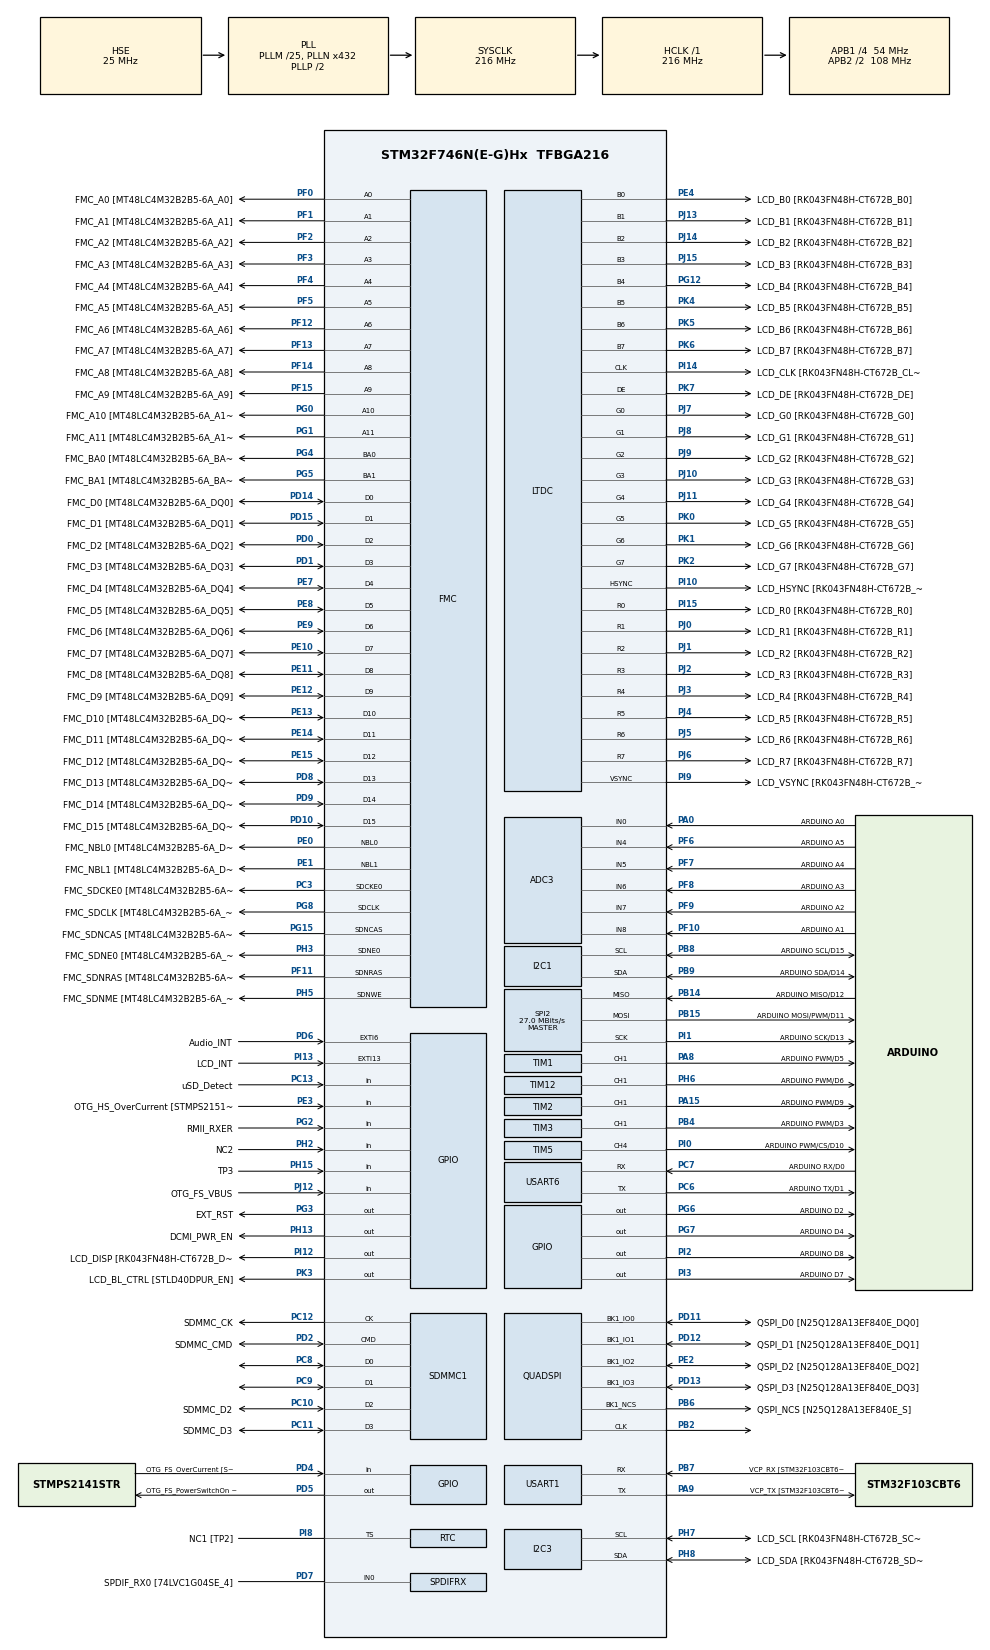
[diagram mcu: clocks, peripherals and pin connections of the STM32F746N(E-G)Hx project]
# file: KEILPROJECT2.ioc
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ADC3.Channel=ADC_CHANNEL_7
ADC3.Channel-0\#ChannelRegularConversion=ADC_CHANNEL_4
ADC3.Channel-IN0=ADC_CHANNEL_0
ADC3.Channel-IN4=ADC_CHANNEL_4
ADC3.Channel-IN5=ADC_CHANNEL_5
ADC3.Channel-IN6=ADC_CHANNEL_6
ADC3.Channel-IN7=ADC_CHANNEL_7
ADC3.Channel-IN8=ADC_CHANNEL_8
CORTEX_M7.CPU_DCache=Enabled
CORTEX_M7.CPU_ICache=Enabled
CORTEX_M7.FlashInterface=TCM_Enabled
I2C1.Timing=0x20404768
I2C3.Timing=0x20404768
LTDC.ActiveH=272
LTDC.ActiveW=480
Mcu.Family=STM32F7
Mcu.Name=STM32F746N(E-G)Hx
Mcu.Package=TFBGA216
NVIC.PriorityGroup=NVIC_PRIORITYGROUP_4
PA0/WKUP.GPIO_Label=ARDUINO A0
PA0/WKUP.GPIO_Mode=GPIO_MODE_ANALOG
PA0/WKUP.GPIO_PuPd=GPIO_NOPULL
PA0/WKUP.Signal=ADCx_IN0
PA1.GPIO_Label=RMII_REF_CLK [LAN8742A-CZ-TR_REFCLK0]
PA1.Signal=ETH_REF_CLK
PA10.GPIO_Label=OTG_FS_ID
PA10.Signal=USB_OTG_FS_ID
PA11.GPIO_Label=OTG_FS_N
PA11.Signal=USB_OTG_FS_DM
PA12.GPIO_Label=OTG_FS_P
PA12.Signal=USB_OTG_FS_DP
PA13.GPIO_Label=SWDIO
PA13.Mode=Serial_Wire
PA13.Signal=SYS_JTMS-SWDIO
PA14.GPIO_Label=SWCLK
PA14.Mode=Serial_Wire
PA14.Signal=SYS_JTCK-SWCLK
PA15.GPIO_Label=ARDUINO PWM/D9
PA15.GPIO_ModeDefaultPP=GPIO_MODE_AF_PP
PA15.GPIO_PuPd=GPIO_NOPULL
PA15.GPIO_Speed=GPIO_SPEED_FREQ_LOW
PA15.Signal=S_TIM2_CH1_ETR
PA2.GPIO_Label=RMII_MDIO [LAN8742A-CZ-TR_MDIO]
PA2.Signal=ETH_MDIO
PA3.GPIO_Label=ULPI_D0 [USB3320C-EZK_D0]
PA3.Signal=USB_OTG_HS_ULPI_D0
PA4.GPIO_Label=DCMI_HSYNC
PA4.Signal=DCMI_HSYNC
PA5.GPIO_Label=ULPI_CLK [USB3320C-EZK_CLKOUT]
PA5.Signal=USB_OTG_HS_ULPI_CK
PA6.Signal=DCMI_PIXCLK
PA7.GPIO_Label=RMII_CRS_DV [LAN8742A-CZ-TR_CRS_DV]
PA7.Signal=ETH_CRS_DV
PA8.GPIO_Label=ARDUINO PWM/D5
PA8.GPIO_ModeDefaultPP=GPIO_MODE_AF_PP
PA8.GPIO_PuPd=GPIO_NOPULL
PA8.GPIO_Speed=GPIO_SPEED_FREQ_LOW
PA8.Signal=S_TIM1_CH1
PA9.GPIO_Label=VCP_TX [STM32F103CBT6_PA3]
PA9.GPIO_Mode=GPIO_MODE_AF_PP
PA9.GPIO_PuPd=GPIO_NOPULL
PA9.GPIO_Speed=GPIO_SPEED_FREQ_LOW
PA9.Mode=Asynchronous
PA9.Signal=USART1_TX
PB0.GPIO_Label=ULPI_D1 [USB3320C-EZK_D1]
PB0.Signal=USB_OTG_HS_ULPI_D1
PB1.GPIO_Label=ULPI_D2 [USB3320C-EZK_D2]
PB1.Signal=USB_OTG_HS_ULPI_D2
PB10.GPIO_Label=ULPI_D3 [USB3320C-EZK_D3]
PB10.Signal=USB_OTG_HS_ULPI_D3
PB11.GPIO_Label=ULPI_D4 [USB3320C-EZK_D4]
PB11.Signal=USB_OTG_HS_ULPI_D4
PB12.GPIO_Label=ULPI_D5 [USB3320C-EZK_D5]
PB12.Signal=USB_OTG_HS_ULPI_D5
PB13.GPIO_Label=ULPI_D6 [USB3320C-EZK_D6]
PB13.Signal=USB_OTG_HS_ULPI_D6
PB14.GPIO_Label=ARDUINO MISO/D12
PB14.GPIO_Mode=GPIO_MODE_AF_PP
PB14.GPIO_PuPd=GPIO_NOPULL
PB14.GPIO_Speed=GPIO_SPEED_FREQ_LOW
PB14.Mode=Full_Duplex_Master
PB14.Signal=SPI2_MISO
PB15.GPIO_Label=ARDUINO MOSI/PWM/D11
PB15.GPIO_Mode=GPIO_MODE_AF_PP
PB15.GPIO_PuPd=GPIO_NOPULL
PB15.GPIO_Speed=GPIO_SPEED_FREQ_LOW
PB15.Mode=Full_Duplex_Master
PB15.Signal=SPI2_MOSI
PB2.Mode=Single Bank 1
PB2.Signal=QUADSPI_CLK
PB3.GPIO_Label=SWO
PB3.Signal=SYS_JTDO-SWO
PB4.GPIO_Label=ARDUINO PWM/D3
PB4.GPIO_ModeDefaultPP=GPIO_MODE_AF_PP
PB4.GPIO_PuPd=GPIO_NOPULL
PB4.GPIO_Speed=GPIO_SPEED_FREQ_LOW
PB4.Signal=S_TIM3_CH1
PB5.GPIO_Label=ULPI_D7 [USB3320C-EZK_D7]
PB5.Signal=USB_OTG_HS_ULPI_D7
PB6.GPIO_Label=QSPI_NCS [N25Q128A13EF840E_S]
PB6.Mode=Single Bank 1
PB6.Signal=QUADSPI_BK1_NCS
PB7.GPIO_Label=VCP_RX [STM32F103CBT6_PA2]
PB7.GPIO_Mode=GPIO_MODE_AF_PP
PB7.GPIO_PuPd=GPIO_NOPULL
PB7.GPIO_Speed=GPIO_SPEED_FREQ_LOW
PB7.Mode=Asynchronous
PB7.Signal=USART1_RX
PB8.GPIO_Label=ARDUINO SCL/D15
PB8.GPIO_Mode=GPIO_MODE_AF_OD
PB8.GPIO_PuPd=GPIO_NOPULL
PB8.GPIO_Speed=GPIO_SPEED_FREQ_LOW
PB8.Mode=I2C
PB8.Signal=I2C1_SCL
PB9.GPIO_Label=ARDUINO SDA/D14
PB9.GPIO_Mode=GPIO_MODE_AF_OD
PB9.GPIO_PuPd=GPIO_NOPULL
PB9.GPIO_Speed=GPIO_SPEED_FREQ_LOW
PB9.Mode=I2C
PB9.Signal=I2C1_SDA
PC0.GPIO_Label=ULPI_STP [USB3320C-EZK_STP]
PC0.Signal=USB_OTG_HS_ULPI_STP
PC1.GPIO_Label=RMII_MDC [LAN8742A-CZ-TR_MDC]
PC1.Signal=ETH_MDC
PC10.GPIO_Label=SDMMC_D2
PC10.Mode=SD_4_bits_Wide_bus
PC10.Signal=SDMMC1_D2
PC11.GPIO_Label=SDMMC_D3
PC11.Mode=SD_4_bits_Wide_bus
PC11.Signal=SDMMC1_D3
PC12.GPIO_Label=SDMMC_CK
PC12.Mode=SD_4_bits_Wide_bus
PC12.Signal=SDMMC1_CK
PC13.GPIO_Label=uSD_Detect
PC13.Signal=GPIO_Input
PC14/OSC32_IN.GPIO_Label=RCC_OSC32_IN
PC14/OSC32_IN.Mode=LSE-External-Oscillator
PC14/OSC32_IN.Signal=RCC_OSC32_IN
PC15/OSC32_OUT.GPIO_Label=RCC_OSC32_OUT
PC15/OSC32_OUT.Mode=LSE-External-Oscillator
PC15/OSC32_OUT.Signal=RCC_OSC32_OUT
PC2.GPIO_Label=ULPI_DIR [USB3320C-EZK_DIR]
PC2.Signal=USB_OTG_HS_ULPI_DIR
PC3.GPIO_Label=FMC_SDCKE0 [MT48LC4M32B2B5-6A_CKE]
PC3.Mode=SdramChipSelect1_1
PC3.Signal=FMC_SDCKE0
PC4.GPIO_Label=RMII_RXD0 [LAN8742A-CZ-TR_RXD0]
PC4.Signal=ETH_RXD0
PC5.GPIO_Label=RMII_RXD1 [LAN8742A-CZ-TR_RXD1]
PC5.Signal=ETH_RXD1
PC6.GPIO_Label=ARDUINO TX/D1
PC6.Mode=Asynchronous
PC6.Signal=USART6_TX
PC7.GPIO_Label=ARDUINO RX/D0
PC7.Mode=Asynchronous
PC7.Signal=USART6_RX
PC8.Mode=SD_4_bits_Wide_bus
PC8.Signal=SDMMC1_D0
PC9.Mode=SD_4_bits_Wide_bus
PC9.Signal=SDMMC1_D1
PD0.GPIO_Label=FMC_D2 [MT48LC4M32B2B5-6A_DQ2]
PD0.Signal=FMC_D2_DA2
PD1.GPIO_Label=FMC_D3 [MT48LC4M32B2B5-6A_DQ3]
PD1.Signal=FMC_D3_DA3
PD10.GPIO_Label=FMC_D15 [MT48LC4M32B2B5-6A_DQ15]
PD10.Signal=FMC_D15_DA15
PD11.GPIO_Label=QSPI_D0 [N25Q128A13EF840E_DQ0]
PD11.Mode=Single Bank 1
PD11.Signal=QUADSPI_BK1_IO0
PD12.GPIO_Label=QSPI_D1 [N25Q128A13EF840E_DQ1]
PD12.Mode=Single Bank 1
PD12.Signal=QUADSPI_BK1_IO1
PD13.GPIO_Label=QSPI_D3 [N25Q128A13EF840E_DQ3]
PD13.Mode=Single Bank 1
PD13.Signal=QUADSPI_BK1_IO3
PD14.GPIO_Label=FMC_D0 [MT48LC4M32B2B5-6A_DQ0]
PD14.Signal=FMC_D0_DA0
PD15.GPIO_Label=FMC_D1 [MT48LC4M32B2B5-6A_DQ1]
PD15.Signal=FMC_D1_DA1
PD2.GPIO_Label=SDMMC_CMD
PD2.Mode=SD_4_bits_Wide_bus
PD2.Signal=SDMMC1_CMD
PD3.GPIO_Label=DCMI_D5
PD3.Signal=DCMI_D5
PD4.GPIO_Label=OTG_FS_OverCurrent [STMPS2141STR_Fault]
PD4.Signal=GPIO_Input
PD5.GPIO_Label=OTG_FS_PowerSwitchOn [STMPS2141STR_EN]
PD5.PinState=GPIO_PIN_SET
PD5.Signal=GPIO_Output
PD6.GPIO_Label=Audio_INT
PD6.GPIO_ModeDefaultEXTI=GPIO_MODE_EVT_RISING
PD6.Signal=GPXTI6
PD7.GPIO_Label=SPDIF_RX0 [74LVC1G04SE_4]
PD7.Mode=IN0
PD7.Signal=SPDIFRX_IN0
PD8.GPIO_Label=FMC_D13 [MT48LC4M32B2B5-6A_DQ13]
PD8.Signal=FMC_D13_DA13
PD9.GPIO_Label=FMC_D14 [MT48LC4M32B2B5-6A_DQ14]
PD9.Signal=FMC_D14_DA14
PE0.GPIO_Label=FMC_NBL0 [MT48LC4M32B2B5-6A_DQM0]
PE0.Signal=FMC_NBL0
PE1.GPIO_Label=FMC_NBL1 [MT48LC4M32B2B5-6A_DQM1]
PE1.Signal=FMC_NBL1
PE10.GPIO_Label=FMC_D7 [MT48LC4M32B2B5-6A_DQ7]
PE10.Signal=FMC_D7_DA7
PE11.GPIO_Label=FMC_D8 [MT48LC4M32B2B5-6A_DQ8]
PE11.Signal=FMC_D8_DA8
PE12.GPIO_Label=FMC_D9 [MT48LC4M32B2B5-6A_DQ9]
PE12.Signal=FMC_D9_DA9
PE13.GPIO_Label=FMC_D10 [MT48LC4M32B2B5-6A_DQ10]
PE13.Signal=FMC_D10_DA10
PE14.GPIO_Label=FMC_D11 [MT48LC4M32B2B5-6A_DQ11]
PE14.Signal=FMC_D11_DA11
PE15.GPIO_Label=FMC_D12 [MT48LC4M32B2B5-6A_DQ12]
PE15.Signal=FMC_D12_DA12
PE2.GPIO_Label=QSPI_D2 [N25Q128A13EF840E_DQ2]
PE2.Mode=Single Bank 1
PE2.Signal=QUADSPI_BK1_IO2
PE3.GPIO_Label=OTG_HS_OverCurrent [STMPS2151STR_FAULT]
PE3.Signal=GPIO_Input
PE4.GPIO_Label=LCD_B0 [RK043FN48H-CT672B_B0]
PE4.Mode=RGB888
PE4.Signal=LTDC_B0
PE5.GPIO_Label=DCMI_D6
PE5.Signal=DCMI_D6
PE6.GPIO_Label=DCMI_D7
PE6.Signal=DCMI_D7
PE7.GPIO_Label=FMC_D4 [MT48LC4M32B2B5-6A_DQ4]
PE7.Signal=FMC_D4_DA4
PE8.GPIO_Label=FMC_D5 [MT48LC4M32B2B5-6A_DQ5]
PE8.Signal=FMC_D5_DA5
PE9.GPIO_Label=FMC_D6 [MT48LC4M32B2B5-6A_DQ6]
PE9.Signal=FMC_D6_DA6
PF0.GPIO_Label=FMC_A0 [MT48LC4M32B2B5-6A_A0]
PF0.Signal=FMC_A0
PF1.GPIO_Label=FMC_A1 [MT48LC4M32B2B5-6A_A1]
PF1.Signal=FMC_A1
PF10.GPIO_Label=ARDUINO A1
PF10.GPIO_Mode=GPIO_MODE_ANALOG
PF10.GPIO_PuPd=GPIO_NOPULL
PF10.Mode=IN8
PF10.Signal=ADC3_IN8
PF11.GPIO_Label=FMC_SDNRAS [MT48LC4M32B2B5-6A_RAS]
PF11.Signal=FMC_SDNRAS
PF12.GPIO_Label=FMC_A6 [MT48LC4M32B2B5-6A_A6]
PF12.Signal=FMC_A6
PF13.GPIO_Label=FMC_A7 [MT48LC4M32B2B5-6A_A7]
PF13.Signal=FMC_A7
PF14.GPIO_Label=FMC_A8 [MT48LC4M32B2B5-6A_A8]
PF14.Signal=FMC_A8
PF15.GPIO_Label=FMC_A9 [MT48LC4M32B2B5-6A_A9]
PF15.Signal=FMC_A9
PF2.GPIO_Label=FMC_A2 [MT48LC4M32B2B5-6A_A2]
PF2.Signal=FMC_A2
PF3.GPIO_Label=FMC_A3 [MT48LC4M32B2B5-6A_A3]
PF3.Signal=FMC_A3
PF4.GPIO_Label=FMC_A4 [MT48LC4M32B2B5-6A_A4]
PF4.Signal=FMC_A4
PF5.GPIO_Label=FMC_A5 [MT48LC4M32B2B5-6A_A5]
PF5.Signal=FMC_A5
PF6.GPIO_Label=ARDUINO A5
PF6.GPIO_Mode=GPIO_MODE_ANALOG
PF6.GPIO_PuPd=GPIO_NOPULL
PF6.Mode=IN4
PF6.Signal=ADC3_IN4
PF7.GPIO_Label=ARDUINO A4
PF7.GPIO_Mode=GPIO_MODE_ANALOG
PF7.GPIO_PuPd=GPIO_NOPULL
PF7.Mode=IN5
PF7.Signal=ADC3_IN5
PF8.GPIO_Label=ARDUINO A3
PF8.GPIO_Mode=GPIO_MODE_ANALOG
PF8.GPIO_PuPd=GPIO_NOPULL
PF8.Mode=IN6
PF8.Signal=ADC3_IN6
PF9.GPIO_Label=ARDUINO A2
PF9.GPIO_Mode=GPIO_MODE_ANALOG
PF9.GPIO_PuPd=GPIO_NOPULL
PF9.Mode=IN7
PF9.Signal=ADC3_IN7
PG0.GPIO_Label=FMC_A10 [MT48LC4M32B2B5-6A_A10]
PG0.Signal=FMC_A10
PG1.GPIO_Label=FMC_A11 [MT48LC4M32B2B5-6A_A11]
PG1.Signal=FMC_A11
PG10.GPIO_Label=SAI2_SDB [WM8994ECS/R_ADCDAT1]
PG10.Signal=SAI2_SD_B
PG11.GPIO_Label=RMII_TX_EN [LAN8742A-CZ-TR_TXEN]
PG11.Signal=ETH_TX_EN
PG12.GPIO_Label=LCD_B4 [RK043FN48H-CT672B_B4]
PG12.Mode=RGB888
PG12.Signal=LTDC_B4
PG13.GPIO_Label=RMII_TXD0 [LAN8742A-CZ-TR_TXD0]
PG13.Signal=ETH_TXD0
PG14.GPIO_Label=RMII_TXD1 [LAN8742A-CZ-TR_TXD1]
PG14.Signal=ETH_TXD1
PG15.GPIO_Label=FMC_SDNCAS [MT48LC4M32B2B5-6A_CAS]
PG15.Signal=FMC_SDNCAS
PG2.GPIO_Label=RMII_RXER
PG2.Signal=GPIO_Input
PG3.GPIO_Label=EXT_RST
PG3.Signal=GPIO_Output
PG4.GPIO_Label=FMC_BA0 [MT48LC4M32B2B5-6A_BA0]
PG4.Signal=FMC_A14_BA0
PG5.GPIO_Label=FMC_BA1 [MT48LC4M32B2B5-6A_BA1]
PG5.Signal=FMC_A15_BA1
PG6.GPIO_Label=ARDUINO D2
PG6.Signal=GPIO_Output
PG7.GPIO_Label=ARDUINO D4
PG7.Signal=GPIO_Output
PG8.GPIO_Label=FMC_SDCLK [MT48LC4M32B2B5-6A_CLK]
PG8.Signal=FMC_SDCLK
PG9.GPIO_Label=DCMI_VSYNC
PG9.Signal=DCMI_VSYNC
PH0/OSC_IN.GPIO_Label=OSC_25M [NZ2520SB-25.00M_OUT]
PH0/OSC_IN.Mode=HSE-External-Oscillator
PH0/OSC_IN.Signal=RCC_OSC_IN
PH1/OSC_OUT.Mode=HSE-External-Oscillator
PH1/OSC_OUT.Signal=RCC_OSC_OUT
PH10.GPIO_Label=DCMI_D1
PH10.Signal=DCMI_D1
PH11.GPIO_Label=DCMI_D2
PH11.Signal=DCMI_D2
PH12.GPIO_Label=DCMI_D3
PH12.Signal=DCMI_D3
PH13.GPIO_Label=DCMI_PWR_EN
PH13.Signal=GPIO_Output
PH14.GPIO_Label=DCMI_D4
PH14.Signal=DCMI_D4
PH15.GPIO_Label=TP3
PH15.Signal=GPIO_Input
PH2.GPIO_Label=NC2
PH2.Signal=GPIO_Input
PH3.GPIO_Label=FMC_SDNE0 [MT48LC4M32B2B5-6A_CS]
PH3.Mode=SdramChipSelect1_1
PH3.Signal=FMC_SDNE0
PH4.GPIO_Label=ULPI_NXT [USB3320C-EZK_NXT]
PH4.Signal=USB_OTG_HS_ULPI_NXT
PH5.GPIO_Label=FMC_SDNME [MT48LC4M32B2B5-6A_WE]
PH5.Signal=FMC_SDNWE
PH6.GPIO_Label=ARDUINO PWM/D6
PH6.Signal=S_TIM12_CH1
PH7.GPIO_Label=LCD_SCL [RK043FN48H-CT672B_SCL]
PH7.Mode=I2C
PH7.Signal=I2C3_SCL
PH8.GPIO_Label=LCD_SDA [RK043FN48H-CT672B_SDA]
PH8.Mode=I2C
PH8.Signal=I2C3_SDA
PH9.GPIO_Label=DCMI_D0
PH9.Signal=DCMI_D0
PI0.GPIO_Label=ARDUINO PWM/CS/D10
PI0.GPIO_ModeDefaultPP=GPIO_MODE_AF_PP
PI0.GPIO_PuPd=GPIO_NOPULL
PI0.GPIO_Speed=GPIO_SPEED_FREQ_LOW
PI0.Signal=S_TIM5_CH4
PI1.GPIO_Label=ARDUINO SCK/D13
PI1.GPIO_Mode=GPIO_MODE_AF_PP
PI1.GPIO_PuPd=GPIO_NOPULL
PI1.GPIO_Speed=GPIO_SPEED_FREQ_LOW
PI1.Mode=Full_Duplex_Master
PI1.Signal=SPI2_SCK
PI10.GPIO_Label=LCD_HSYNC [RK043FN48H-CT672B_HSYNC]
PI10.Mode=RGB888
PI10.Signal=LTDC_HSYNC
PI12.GPIO_Label=LCD_DISP [RK043FN48H-CT672B_DISP] 
PI12.Signal=GPIO_Output
PI13.GPIO_Label=LCD_INT
PI13.GPIO_ModeDefaultEXTI=GPIO_MODE_EVT_RISING
PI13.Signal=GPXTI13
PI14.GPIO_Label=LCD_CLK [RK043FN48H-CT672B_CLK]
PI14.Mode=RGB888
PI14.Signal=LTDC_CLK
PI15.GPIO_Label=LCD_R0 [RK043FN48H-CT672B_R0]
PI15.Mode=RGB888
PI15.Signal=LTDC_R0
PI2.GPIO_Label=ARDUINO D8
PI2.Signal=GPIO_Output
PI3.GPIO_Label=ARDUINO D7
PI3.Signal=GPIO_Output
PI4.GPIO_Label=SAI2_MCLKA [WM8994ECS/R_MCLK1]
PI4.Signal=SAI2_MCLK_A
PI5.GPIO_Label=SAI2_SCKA [WM8994ECS/R_BCLK1]
PI5.Signal=SAI2_SCK_A
PI6.GPIO_Label=SAI2_SDA [WM8994ECS/R_DACDAT1]
PI6.Signal=SAI2_SD_A
PI7.GPIO_Label=SAI2_FSA [WM8994ECS/R_LRCLK1]
PI7.Signal=SAI2_FS_A
PI8.GPIO_Label=NC1 [TP2]
PI8.Mode=Timestamp enabled - Input Enabled to TS
PI8.Signal=RTC_TS
PI9.GPIO_Label=LCD_VSYNC [RK043FN48H-CT672B_VSYNC]
PI9.Mode=RGB888
PI9.Signal=LTDC_VSYNC
PJ0.GPIO_Label=LCD_R1 [RK043FN48H-CT672B_R1]
PJ0.Mode=RGB888
PJ0.Signal=LTDC_R1
PJ1.GPIO_Label=LCD_R2 [RK043FN48H-CT672B_R2]
PJ1.Mode=RGB888
PJ1.Signal=LTDC_R2
PJ10.GPIO_Label=LCD_G3 [RK043FN48H-CT672B_G3]
PJ10.Mode=RGB888
PJ10.Signal=LTDC_G3
PJ11.GPIO_Label=LCD_G4 [RK043FN48H-CT672B_G4]
PJ11.Mode=RGB888
PJ11.Signal=LTDC_G4
PJ12.GPIO_Label=OTG_FS_VBUS
PJ12.Signal=GPIO_Input
PJ13.GPIO_Label=LCD_B1 [RK043FN48H-CT672B_B1]
PJ13.Mode=RGB888
PJ13.Signal=LTDC_B1
PJ14.GPIO_Label=LCD_B2 [RK043FN48H-CT672B_B2]
PJ14.Mode=RGB888
PJ14.Signal=LTDC_B2
PJ15.GPIO_Label=LCD_B3 [RK043FN48H-CT672B_B3]
PJ15.Mode=RGB888
PJ15.Signal=LTDC_B3
PJ2.GPIO_Label=LCD_R3 [RK043FN48H-CT672B_R3]
PJ2.Mode=RGB888
PJ2.Signal=LTDC_R3
PJ3.GPIO_Label=LCD_R4 [RK043FN48H-CT672B_R4]
PJ3.Mode=RGB888
PJ3.Signal=LTDC_R4
PJ4.GPIO_Label=LCD_R5 [RK043FN48H-CT672B_R5]
PJ4.Mode=RGB888
PJ4.Signal=LTDC_R5
PJ5.GPIO_Label=LCD_R6 [RK043FN48H-CT672B_R6]
PJ5.Mode=RGB888
PJ5.Signal=LTDC_R6
PJ6.GPIO_Label=LCD_R7 [RK043FN48H-CT672B_R7]
PJ6.Mode=RGB888
PJ6.Signal=LTDC_R7
PJ7.GPIO_Label=LCD_G0 [RK043FN48H-CT672B_G0]
PJ7.Mode=RGB888
PJ7.Signal=LTDC_G0
PJ8.GPIO_Label=LCD_G1 [RK043FN48H-CT672B_G1]
PJ8.Mode=RGB888
PJ8.Signal=LTDC_G1
PJ9.GPIO_Label=LCD_G2 [RK043FN48H-CT672B_G2]
PJ9.Mode=RGB888
PJ9.Signal=LTDC_G2
PK0.GPIO_Label=LCD_G5 [RK043FN48H-CT672B_G5]
PK0.Mode=RGB888
PK0.Signal=LTDC_G5
PK1.GPIO_Label=LCD_G6 [RK043FN48H-CT672B_G6]
PK1.Mode=RGB888
PK1.Signal=LTDC_G6
PK2.GPIO_Label=LCD_G7 [RK043FN48H-CT672B_G7]
PK2.Mode=RGB888
PK2.Signal=LTDC_G7
PK3.GPIO_Label=LCD_BL_CTRL [STLD40DPUR_EN]
PK3.Signal=GPIO_Output
PK4.GPIO_Label=LCD_B5 [RK043FN48H-CT672B_B5]
PK4.Mode=RGB888
PK4.Signal=LTDC_B5
PK5.GPIO_Label=LCD_B6 [RK043FN48H-CT672B_B6]
PK5.Mode=RGB888
PK5.Signal=LTDC_B6
PK6.GPIO_Label=LCD_B7 [RK043FN48H-CT672B_B7]
PK6.Mode=RGB888
PK6.Signal=LTDC_B7
PK7.GPIO_Label=LCD_DE [RK043FN48H-CT672B_DE]
PK7.Mode=RGB888
PK7.Signal=LTDC_DE
ProjectManager.HeapSize=0x200
ProjectManager.StackSize=0x3000
ProjectManager.TargetToolchain=MDK-ARM V5
RCC.AHBFreq_Value=216000000
RCC.APB1CLKDivider=RCC_HCLK_DIV4
RCC.APB1Freq_Value=54000000
RCC.APB1TimFreq_Value=108000000
RCC.APB2CLKDivider=RCC_HCLK_DIV2
RCC.APB2Freq_Value=108000000
RCC.APB2TimFreq_Value=216000000
RCC.CortexFreq_Value=216000000
RCC.HCLKFreq_Value=216000000
RCC.HSE_VALUE=25000000
RCC.HSI_VALUE=16000000
RCC.PLLI2SN=100
RCC.PLLM=25
RCC.PLLN=432
RCC.PLLQ=9
RCC.PLLSAIN=100
RCC.PLLSourceVirtual=RCC_PLLSOURCE_HSE
RCC.SDMMCClockSelection=RCC_SDMMC1CLKSOURCE_CLK48
RCC.SYSCLKFreq_VALUE=216000000
RCC.SYSCLKSource=RCC_SYSCLKSOURCE_PLLCLK
RCC.USBFreq_Value=48000000
RCC.VCOOutputFreq_Value=432000000
RTC.Alarm-Alarm\ A=RTC_ALARM_A
RTC.Alarm_B-Alarm\ B=RTC_ALARM_B
SDMMC1.ClockDiv=2
SH.ADCx_IN0.0=ADC3_IN0,IN0
SH.FMC_A0.0=FMC_A0,12b-sda1
SH.FMC_A1.0=FMC_A1,12b-sda1
SH.FMC_A10.0=FMC_A10,12b-sda1
SH.FMC_A11.0=FMC_A11,12b-sda1
SH.FMC_A14_BA0.0=FMC_BA0,FourSdramBanks1
SH.FMC_A15_BA1.0=FMC_BA1,FourSdramBanks1
SH.FMC_A2.0=FMC_A2,12b-sda1
SH.FMC_A3.0=FMC_A3,12b-sda1
SH.FMC_A4.0=FMC_A4,12b-sda1
SH.FMC_A5.0=FMC_A5,12b-sda1
SH.FMC_A6.0=FMC_A6,12b-sda1
SH.FMC_A7.0=FMC_A7,12b-sda1
SH.FMC_A8.0=FMC_A8,12b-sda1
SH.FMC_A9.0=FMC_A9,12b-sda1
SH.FMC_D0_DA0.0=FMC_D0,sd-16b-d1
SH.FMC_D10_DA10.0=FMC_D10,sd-16b-d1
SH.FMC_D11_DA11.0=FMC_D11,sd-16b-d1
SH.FMC_D12_DA12.0=FMC_D12,sd-16b-d1
SH.FMC_D13_DA13.0=FMC_D13,sd-16b-d1
SH.FMC_D14_DA14.0=FMC_D14,sd-16b-d1
SH.FMC_D15_DA15.0=FMC_D15,sd-16b-d1
SH.FMC_D1_DA1.0=FMC_D1,sd-16b-d1
SH.FMC_D2_DA2.0=FMC_D2,sd-16b-d1
SH.FMC_D3_DA3.0=FMC_D3,sd-16b-d1
SH.FMC_D4_DA4.0=FMC_D4,sd-16b-d1
SH.FMC_D5_DA5.0=FMC_D5,sd-16b-d1
SH.FMC_D6_DA6.0=FMC_D6,sd-16b-d1
SH.FMC_D7_DA7.0=FMC_D7,sd-16b-d1
SH.FMC_D8_DA8.0=FMC_D8,sd-16b-d1
SH.FMC_D9_DA9.0=FMC_D9,sd-16b-d1
SH.FMC_NBL0.0=FMC_NBL0,Sd2ByteEnable1
SH.FMC_NBL1.0=FMC_NBL1,Sd2ByteEnable1
SH.FMC_SDCLK.0=FMC_SDCLK,12b-sda1
SH.FMC_SDNCAS.0=FMC_SDNCAS,12b-sda1
SH.FMC_SDNRAS.0=FMC_SDNRAS,12b-sda1
SH.FMC_SDNWE.0=FMC_SDNWE,12b-sda1
SH.S_TIM12_CH1.0=TIM12_CH1,PWM Generation1 CH1
SH.S_TIM1_CH1.0=TIM1_CH1,PWM Generation1 CH1
SH.S_TIM2_CH1_ETR.0=TIM2_CH1,PWM Generation1 CH1
SH.S_TIM3_CH1.0=TIM3_CH1,PWM Generation1 CH1
SH.S_TIM5_CH4.0=TIM5_CH4,PWM Generation4 CH4
SPI2.CalculateBaudRate=27.0 MBits/s
SPI2.Direction=SPI_DIRECTION_2LINES
SPI2.Mode=SPI_MODE_MASTER
SPI2.VirtualType=VM_MASTER
TIM1.Channel-PWM\ Generation1\ CH1=TIM_CHANNEL_1
TIM12.Channel-PWM\ Generation1\ CH1=TIM_CHANNEL_1
TIM2.Channel-PWM\ Generation1\ CH1=TIM_CHANNEL_1
TIM3.Channel-PWM\ Generation1\ CH1=TIM_CHANNEL_1
TIM5.Channel-PWM\ Generation4\ CH4=TIM_CHANNEL_4
USART1.VirtualMode-Asynchronous=VM_ASYNC
USART6.VirtualMode-Asynchronous=VM_ASYNC
VP_FATFS_VS_SDIO.Mode=SDIO
VP_RTC_VS_RTC_Activate.Mode=RTC_Enabled
VP_RTC_VS_RTC_Alarm_A_Intern.Mode=Alarm A
VP_RTC_VS_RTC_Alarm_B_Intern.Mode=Alarm B
VP_RTC_VS_RTC_Calendar.Mode=RTC_Calendar
VP_TIM1_VS_ClockSourceINT.Mode=Internal
VP_TIM2_VS_ClockSourceINT.Mode=Internal
VP_TIM3_VS_ClockSourceINT.Mode=Internal
VP_TIM5_VS_ClockSourceINT.Mode=Internal
VP_TIM8_VS_ClockSourceINT.Mode=Internal
board=STM32F746G-DISCO

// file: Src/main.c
/**
  ******************************************************************************
  * File Name          : main.c
  * Description        : Main program body
  ******************************************************************************
  * This notice applies to any and all portions of this file
  * that are not between comment pairs USER CODE BEGIN and
  * USER CODE END. Other portions of this file, whether
  * inserted by the user or by software development tools
  * are owned by their respective copyright owners.
  *
  * Copyright (c) 2017 STMicroelectronics International N.V.
  * All rights reserved.
  *
  * Redistribution and use in source and binary forms, with or without
  * modification, are permitted, provided that the following conditions are met:
  *
  * 1. Redistribution of source code must retain the above copyright notice,
  *    this list of conditions and the following disclaimer.
  * 2. Redistributions in binary form must reproduce the above copyright notice,
  *    this list of conditions and the following disclaimer in the documentation
  *    and/or other materials provided with the distribution.
  * 3. Neither the name of STMicroelectronics nor the names of other
  *    contributors to this software may be used to endorse or promote products
  *    derived from this software without specific written permission.
  * 4. This software, including modifications and/or derivative works of this
  *    software, must execute solely and exclusively on microcontroller or
  *    microprocessor devices manufactured by or for STMicroelectronics.
  * 5. Redistribution and use of this software other than as permitted under
  *    this license is void and will automatically terminate your rights under
  *    this license.
  *
  * THIS SOFTWARE IS PROVIDED BY STMICROELECTRONICS AND CONTRIBUTORS "AS IS"
  * AND ANY EXPRESS, IMPLIED OR STATUTORY WARRANTIES, INCLUDING, BUT NOT
  * LIMITED TO, THE IMPLIED WARRANTIES OF MERCHANTABILITY, FITNESS FOR A
  * PARTICULAR PURPOSE AND NON-INFRINGEMENT OF THIRD PARTY INTELLECTUAL PROPERTY
  * RIGHTS ARE DISCLAIMED TO THE FULLEST EXTENT PERMITTED BY LAW. IN NO EVENT
  * SHALL STMICROELECTRONICS OR CONTRIBUTORS BE LIABLE FOR ANY DIRECT, INDIRECT,
  * INCIDENTAL, SPECIAL, EXEMPLARY, OR CONSEQUENTIAL DAMAGES (INCLUDING, BUT NOT
  * LIMITED TO, PROCUREMENT OF SUBSTITUTE GOODS OR SERVICES; LOSS OF USE, DATA,
  * OR PROFITS; OR BUSINESS INTERRUPTION) HOWEVER CAUSED AND ON ANY THEORY OF
  * LIABILITY, WHETHER IN CONTRACT, STRICT LIABILITY, OR TORT (INCLUDING
  * NEGLIGENCE OR OTHERWISE) ARISING IN ANY WAY OUT OF THE USE OF THIS SOFTWARE,
  * EVEN IF ADVISED OF THE POSSIBILITY OF SUCH DAMAGE.
  *
  ******************************************************************************
  */
#include "main.h"
#include "stm32f7xx_hal.h"
#include "fatfs.h"

/* USER CODE BEGIN Includes */

//YTB tutorial method S @ //<<<<SD CARD file writing demo>>>S>>
FRESULT res;
FATFS SDFatFS;
FIL myFile;
char bufferwr[30] = "Manojkumar\r\n" ;
char bufferrd[30];
char SDPath[10];
uint32_t byteswritten, bytesread;
extern void runonce();
extern void guiEventLoop(void);
enum _bool
{
false = 0,
true =1
};typedef enum _bool boolean;

//YTB tutorial method E

/*<<---------TEST_CODES----S----->>*/
/*UGFX NOTEPAD CODE BEGIN*/
//#define COLOFR_SIZE	20
//#define PEN_SIZE	20
//#define OFFSET		3

//#define COLOR_BOX(a)		(ev.x >= a && ev.x <= a + COLOR_SIZE)
//#define PEN_BOX(a)			(ev.y >= a && ev.y <= a + COLOR_SIZE)
//#define GET_COLOR(a)		(COLOR_BOX(a * COLOR_SIZE + OFFSET))
//#define GET_PEN(a)			(PEN_BOX(a * 2 * PEN_SIZE + OFFSET))
//#define DRAW_COLOR(a)		(a * COLOR_SIZE + OFFSET)
//#define DRAW_PEN(a)			(a * 2 * PEN_SIZE + OFFSET)
//#define DRAW_AREA(x, y)		(x >= PEN_SIZE + OFFSET + 3 && x <= gdispGetWidth() && \
//							 y >= COLOR_SIZE + OFFSET + 3 && y <= gdispGetHeight())
//#include "gfx.h"
//#include "gui.h"
//#include "ugfx_ex.h"
/*UGFX NOTEPAD CODE END*/

//NOTEPAD GUI RELATED BEGIN/
//		extern void gfxInit(void);
//		extern void drawScreen(void);
//extern void rundisplay(void);
//NOTEPAD GUI RELATED END*/
/*<<---------TEST_CODES----E----->>*/
extern int ugfxfatfsdemo();
/* USER CODE END Includes */

ADC_HandleTypeDef hadc3;

I2C_HandleTypeDef hi2c1;
I2C_HandleTypeDef hi2c3;

LTDC_HandleTypeDef hltdc;

QSPI_HandleTypeDef hqspi;

RTC_HandleTypeDef hrtc;

SD_HandleTypeDef hsd1;

SPDIFRX_HandleTypeDef hspdif;

SPI_HandleTypeDef hspi2;

TIM_HandleTypeDef htim1;
TIM_HandleTypeDef htim2;
TIM_HandleTypeDef htim3;
TIM_HandleTypeDef htim5;
TIM_HandleTypeDef htim8;
TIM_HandleTypeDef htim12;

UART_HandleTypeDef huart1;
UART_HandleTypeDef huart6;

SDRAM_HandleTypeDef hsdram1;

/* USER CODE BEGIN PV */
/* Private variables ---------------------------------------------------------*/

/* USER CODE END PV */

void SystemClock_Config(void);
static void MX_GPIO_Init(void);
static void MX_ADC3_Init(void);
static void MX_FMC_Init(void);
static void MX_I2C1_Init(void);
static void MX_I2C3_Init(void);
static void MX_LTDC_Init(void);
static void MX_QUADSPI_Init(void);
static void MX_RTC_Init(void);
static void MX_SDMMC1_SD_Init(void);
static void MX_SPDIFRX_Init(void);
static void MX_SPI2_Init(void);
static void MX_TIM1_Init(void);
static void MX_TIM2_Init(void);
static void MX_TIM3_Init(void);
static void MX_TIM5_Init(void);
static void MX_TIM8_Init(void);
static void MX_TIM12_Init(void);
static void MX_USART1_UART_Init(void);
static void MX_USART6_UART_Init(void);

void HAL_TIM_MspPostInit(TIM_HandleTypeDef *htim);

/* USER CODE BEGIN PFP */
/* Private function prototypes -----------------------------------------------*/

/* USER CODE END PFP */

/* USER CODE BEGIN 0 */
//int RoughAdjValue = 10;
//GEventMouse		ev;
/* USER CODE END 0 */

int main(void)
{

  /* Enable I-Cache-------------------------------------------------------------*/
  SCB_EnableICache();

  /* Enable D-Cache-------------------------------------------------------------*/
  SCB_EnableDCache();

  /* MCU Configuration----------------------------------------------------------*/

  /* Reset of all peripherals, Initializes the Flash interface and the Systick. */
  HAL_Init();

  /* Configure the system clock */
  SystemClock_Config();

  /* Initialize all configured peripherals */
  MX_GPIO_Init();
  MX_ADC3_Init();
  MX_FMC_Init();
  MX_I2C1_Init();
  MX_I2C3_Init();
  MX_LTDC_Init();
  MX_QUADSPI_Init();
  MX_RTC_Init();
  MX_SDMMC1_SD_Init();
  MX_SPDIFRX_Init();
  MX_SPI2_Init();
  MX_TIM1_Init();
  MX_TIM2_Init();
  MX_TIM3_Init();
  MX_TIM5_Init();
  MX_TIM8_Init();
  MX_TIM12_Init();
  MX_USART1_UART_Init();
  MX_USART6_UART_Init();
  MX_FATFS_Init();

  /* USER CODE BEGIN 2 */
	 //<<<<SD CARD file writing demo>>>S>>
	 res = BSP_SD_Init();
	 res = f_mount(&SDFatFS, "", 1);
	 res = f_open(&myFile, "manoj.txt", FA_OPEN_ALWAYS|FA_WRITE|FA_WRITE);
	 res = f_lseek(&myFile, f_size(&myFile));
	 //f_printf(&myFile, "%s", bufferwr);
	 f_close(&myFile);
	 //<<<<SD CARD file writing demo>>>E>>
		//runonce();
		//guiEventLoop();
	 rundisplay();
	 //ugfxfatfsdemo();
  /* USER CODE END 2 */

  /* Infinite loop */
  while (1)
  {

  }

}

/** System Clock Configuration
*/
void SystemClock_Config(void)
{

  RCC_OscInitTypeDef RCC_OscInitStruct;
  RCC_ClkInitTypeDef RCC_ClkInitStruct;
  RCC_PeriphCLKInitTypeDef PeriphClkInitStruct;

    /**Configure the main internal regulator output voltage
    */
  __HAL_RCC_PWR_CLK_ENABLE();

  __HAL_PWR_VOLTAGESCALING_CONFIG(PWR_REGULATOR_VOLTAGE_SCALE1);

    /**Initializes the CPU, AHB and APB busses clocks
    */
  RCC_OscInitStruct.OscillatorType = RCC_OSCILLATORTYPE_LSI|RCC_OSCILLATORTYPE_HSE;
  RCC_OscInitStruct.HSEState = RCC_HSE_ON;
  RCC_OscInitStruct.LSIState = RCC_LSI_ON;
  RCC_OscInitStruct.PLL.PLLState = RCC_PLL_ON;
  RCC_OscInitStruct.PLL.PLLSource = RCC_PLLSOURCE_HSE;
  RCC_OscInitStruct.PLL.PLLM = 25;
  RCC_OscInitStruct.PLL.PLLN = 432;
  RCC_OscInitStruct.PLL.PLLP = RCC_PLLP_DIV2;
  RCC_OscInitStruct.PLL.PLLQ = 9;
  if (HAL_RCC_OscConfig(&RCC_OscInitStruct) != HAL_OK)
  {
    _Error_Handler(__FILE__, __LINE__);
  }

    /**Activate the Over-Drive mode
    */
  if (HAL_PWREx_EnableOverDrive() != HAL_OK)
  {
    _Error_Handler(__FILE__, __LINE__);
  }

    /**Initializes the CPU, AHB and APB busses clocks
    */
  RCC_ClkInitStruct.ClockType = RCC_CLOCKTYPE_HCLK|RCC_CLOCKTYPE_SYSCLK
                              |RCC_CLOCKTYPE_PCLK1|RCC_CLOCKTYPE_PCLK2;
  RCC_ClkInitStruct.SYSCLKSource = RCC_SYSCLKSOURCE_PLLCLK;
  RCC_ClkInitStruct.AHBCLKDivider = RCC_SYSCLK_DIV1;
  RCC_ClkInitStruct.APB1CLKDivider = RCC_HCLK_DIV4;
  RCC_ClkInitStruct.APB2CLKDivider = RCC_HCLK_DIV2;

  if (HAL_RCC_ClockConfig(&RCC_ClkInitStruct, FLASH_LATENCY_7) != HAL_OK)
  {
    _Error_Handler(__FILE__, __LINE__);
  }

  PeriphClkInitStruct.PeriphClockSelection = RCC_PERIPHCLK_SPDIFRX|RCC_PERIPHCLK_LTDC
                              |RCC_PERIPHCLK_RTC|RCC_PERIPHCLK_USART1
                              |RCC_PERIPHCLK_USART6|RCC_PERIPHCLK_I2C1
                              |RCC_PERIPHCLK_I2C3|RCC_PERIPHCLK_SDMMC1
                              |RCC_PERIPHCLK_CLK48;
  PeriphClkInitStruct.PLLI2S.PLLI2SN = 100;
  PeriphClkInitStruct.PLLI2S.PLLI2SP = RCC_PLLP_DIV2;
  PeriphClkInitStruct.PLLI2S.PLLI2SR = 2;
  PeriphClkInitStruct.PLLI2S.PLLI2SQ = 2;
  PeriphClkInitStruct.PLLSAI.PLLSAIN = 100;
  PeriphClkInitStruct.PLLSAI.PLLSAIR = 2;
  PeriphClkInitStruct.PLLSAI.PLLSAIQ = 2;
  PeriphClkInitStruct.PLLSAI.PLLSAIP = RCC_PLLSAIP_DIV2;
  PeriphClkInitStruct.PLLI2SDivQ = 1;
  PeriphClkInitStruct.PLLSAIDivQ = 1;
  PeriphClkInitStruct.PLLSAIDivR = RCC_PLLSAIDIVR_2;
  PeriphClkInitStruct.RTCClockSelection = RCC_RTCCLKSOURCE_LSI;
  PeriphClkInitStruct.Usart1ClockSelection = RCC_USART1CLKSOURCE_PCLK2;
  PeriphClkInitStruct.Usart6ClockSelection = RCC_USART6CLKSOURCE_PCLK2;
  PeriphClkInitStruct.I2c1ClockSelection = RCC_I2C1CLKSOURCE_PCLK1;
  PeriphClkInitStruct.I2c3ClockSelection = RCC_I2C3CLKSOURCE_PCLK1;
  PeriphClkInitStruct.Clk48ClockSelection = RCC_CLK48SOURCE_PLL;
  PeriphClkInitStruct.Sdmmc1ClockSelection = RCC_SDMMC1CLKSOURCE_CLK48;
  if (HAL_RCCEx_PeriphCLKConfig(&PeriphClkInitStruct) != HAL_OK)
  {
    _Error_Handler(__FILE__, __LINE__);
  }

    /**Configure the Systick interrupt time
    */
  HAL_SYSTICK_Config(HAL_RCC_GetHCLKFreq()/1000);

    /**Configure the Systick
    */
  HAL_SYSTICK_CLKSourceConfig(SYSTICK_CLKSOURCE_HCLK);

  /* SysTick_IRQn interrupt configuration */
  HAL_NVIC_SetPriority(SysTick_IRQn, 0, 0);
}

/* ADC3 init function */
static void MX_ADC3_Init(void)
{

  ADC_ChannelConfTypeDef sConfig;

    /**Configure the global features of the ADC (Clock, Resolution, Data Alignment and number of conversion)
    */
  hadc3.Instance = ADC3;
  hadc3.Init.ClockPrescaler = ADC_CLOCK_SYNC_PCLK_DIV4;
  hadc3.Init.Resolution = ADC_RESOLUTION_12B;
  hadc3.Init.ScanConvMode = DISABLE;
  hadc3.Init.ContinuousConvMode = DISABLE;
  hadc3.Init.DiscontinuousConvMode = DISABLE;
  hadc3.Init.ExternalTrigConvEdge = ADC_EXTERNALTRIGCONVEDGE_NONE;
  hadc3.Init.ExternalTrigConv = ADC_SOFTWARE_START;
  hadc3.Init.DataAlign = ADC_DATAALIGN_RIGHT;
  hadc3.Init.NbrOfConversion = 1;
  hadc3.Init.DMAContinuousRequests = DISABLE;
  hadc3.Init.EOCSelection = ADC_EOC_SINGLE_CONV;
  if (HAL_ADC_Init(&hadc3) != HAL_OK)
  {
    _Error_Handler(__FILE__, __LINE__);
  }

    /**Configure for the selected ADC regular channel its corresponding rank in the sequencer and its sample time.
    */
  sConfig.Channel = ADC_CHANNEL_4;
  sConfig.Rank = 1;
  sConfig.SamplingTime = ADC_SAMPLETIME_3CYCLES;
  if (HAL_ADC_ConfigChannel(&hadc3, &sConfig) != HAL_OK)
  {
    _Error_Handler(__FILE__, __LINE__);
  }

}

/* I2C1 init function */
static void MX_I2C1_Init(void)
{

  hi2c1.Instance = I2C1;
  hi2c1.Init.Timing = 0x20404768;
  hi2c1.Init.OwnAddress1 = 0;
  hi2c1.Init.AddressingMode = I2C_ADDRESSINGMODE_7BIT;
  hi2c1.Init.DualAddressMode = I2C_DUALADDRESS_DISABLE;
  hi2c1.Init.OwnAddress2 = 0;
  hi2c1.Init.OwnAddress2Masks = I2C_OA2_NOMASK;
  hi2c1.Init.GeneralCallMode = I2C_GENERALCALL_DISABLE;
  hi2c1.Init.NoStretchMode = I2C_NOSTRETCH_DISABLE;
  if (HAL_I2C_Init(&hi2c1) != HAL_OK)
  {
    _Error_Handler(__FILE__, __LINE__);
  }

    /**Configure Analogue filter
    */
  if (HAL_I2CEx_ConfigAnalogFilter(&hi2c1, I2C_ANALOGFILTER_ENABLE) != HAL_OK)
  {
    _Error_Handler(__FILE__, __LINE__);
  }

    /**Configure Digital filter
    */
  if (HAL_I2CEx_ConfigDigitalFilter(&hi2c1, 0) != HAL_OK)
  {
    _Error_Handler(__FILE__, __LINE__);
  }

}

/* I2C3 init function */
static void MX_I2C3_Init(void)
{

  hi2c3.Instance = I2C3;
  hi2c3.Init.Timing = 0x20404768;
  hi2c3.Init.OwnAddress1 = 0;
  hi2c3.Init.AddressingMode = I2C_ADDRESSINGMODE_7BIT;
  hi2c3.Init.DualAddressMode = I2C_DUALADDRESS_DISABLE;
  hi2c3.Init.OwnAddress2 = 0;
  hi2c3.Init.OwnAddress2Masks = I2C_OA2_NOMASK;
  hi2c3.Init.GeneralCallMode = I2C_GENERALCALL_DISABLE;
  hi2c3.Init.NoStretchMode = I2C_NOSTRETCH_DISABLE;
  if (HAL_I2C_Init(&hi2c3) != HAL_OK)
  {
    _Error_Handler(__FILE__, __LINE__);
  }

    /**Configure Analogue filter
    */
  if (HAL_I2CEx_ConfigAnalogFilter(&hi2c3, I2C_ANALOGFILTER_ENABLE) != HAL_OK)
  {
    _Error_Handler(__FILE__, __LINE__);
  }

    /**Configure Digital filter
    */
  if (HAL_I2CEx_ConfigDigitalFilter(&hi2c3, 0) != HAL_OK)
  {
    _Error_Handler(__FILE__, __LINE__);
  }

}

/* LTDC init function */
static void MX_LTDC_Init(void)
{

  LTDC_LayerCfgTypeDef pLayerCfg;
  LTDC_LayerCfgTypeDef pLayerCfg1;

  hltdc.Instance = LTDC;
  hltdc.Init.HSPolarity = LTDC_HSPOLARITY_AL;
  hltdc.Init.VSPolarity = LTDC_VSPOLARITY_AL;
  hltdc.Init.DEPolarity = LTDC_DEPOLARITY_AL;
  hltdc.Init.PCPolarity = LTDC_PCPOLARITY_IPC;
  hltdc.Init.HorizontalSync = 7;
  hltdc.Init.VerticalSync = 3;
  hltdc.Init.AccumulatedHBP = 14;
  hltdc.Init.AccumulatedVBP = 5;
  hltdc.Init.AccumulatedActiveW = 494;
  hltdc.Init.AccumulatedActiveH = 277;
  hltdc.Init.TotalWidth = 500;
  hltdc.Init.TotalHeigh = 279;
  hltdc.Init.Backcolor.Blue = 0;
  hltdc.Init.Backcolor.Green = 0;
  hltdc.Init.Backcolor.Red = 0;
  if (HAL_LTDC_Init(&hltdc) != HAL_OK)
  {
    _Error_Handler(__FILE__, __LINE__);
  }

  pLayerCfg.WindowX0 = 0;
  pLayerCfg.WindowX1 = 0;
  pLayerCfg.WindowY0 = 0;
  pLayerCfg.WindowY1 = 0;
  pLayerCfg.PixelFormat = LTDC_PIXEL_FORMAT_ARGB8888;
  pLayerCfg.Alpha = 0;
  pLayerCfg.Alpha0 = 0;
  pLayerCfg.BlendingFactor1 = LTDC_BLENDING_FACTOR1_CA;
  pLayerCfg.BlendingFactor2 = LTDC_BLENDING_FACTOR2_CA;
  pLayerCfg.FBStartAdress = 0;
  pLayerCfg.ImageWidth = 0;
  pLayerCfg.ImageHeight = 0;
  pLayerCfg.Backcolor.Blue = 0;
  pLayerCfg.Backcolor.Green = 0;
  pLayerCfg.Backcolor.Red = 0;
  if (HAL_LTDC_ConfigLayer(&hltdc, &pLayerCfg, 0) != HAL_OK)
  {
    _Error_Handler(__FILE__, __LINE__);
  }

  pLayerCfg1.WindowX0 = 0;
  pLayerCfg1.WindowX1 = 0;
  pLayerCfg1.WindowY0 = 0;
  pLayerCfg1.WindowY1 = 0;
  pLayerCfg1.PixelFormat = LTDC_PIXEL_FORMAT_ARGB8888;
  pLayerCfg1.Alpha = 0;
  pLayerCfg1.Alpha0 = 0;
  pLayerCfg1.BlendingFactor1 = LTDC_BLENDING_FACTOR1_CA;
  pLayerCfg1.BlendingFactor2 = LTDC_BLENDING_FACTOR2_CA;
  pLayerCfg1.FBStartAdress = 0;
  pLayerCfg1.ImageWidth = 0;
  pLayerCfg1.ImageHeight = 0;
  pLayerCfg1.Backcolor.Blue = 0;
  pLayerCfg1.Backcolor.Green = 0;
  pLayerCfg1.Backcolor.Red = 0;
  if (HAL_LTDC_ConfigLayer(&hltdc, &pLayerCfg1, 1) != HAL_OK)
  {
    _Error_Handler(__FILE__, __LINE__);
  }

}

/* QUADSPI init function */
static void MX_QUADSPI_Init(void)
{

  hqspi.Instance = QUADSPI;
  hqspi.Init.ClockPrescaler = 255;
  hqspi.Init.FifoThreshold = 1;
  hqspi.Init.SampleShifting = QSPI_SAMPLE_SHIFTING_NONE;
  hqspi.Init.FlashSize = 1;
  hqspi.Init.ChipSelectHighTime = QSPI_CS_HIGH_TIME_1_CYCLE;
  hqspi.Init.ClockMode = QSPI_CLOCK_MODE_0;
  hqspi.Init.FlashID = QSPI_FLASH_ID_1;
  hqspi.Init.DualFlash = QSPI_DUALFLASH_DISABLE;
  if (HAL_QSPI_Init(&hqspi) != HAL_OK)
  {
    _Error_Handler(__FILE__, __LINE__);
  }

}

/* RTC init function */
static void MX_RTC_Init(void)
{

  RTC_TimeTypeDef sTime;
  RTC_DateTypeDef sDate;
  RTC_AlarmTypeDef sAlarm;

    /**Initialize RTC Only
    */
  hrtc.Instance = RTC;
  hrtc.Init.HourFormat = RTC_HOURFORMAT_24;
  hrtc.Init.AsynchPrediv = 127;
  hrtc.Init.SynchPrediv = 255;
  hrtc.Init.OutPut = RTC_OUTPUT_DISABLE;
  hrtc.Init.OutPutPolarity = RTC_OUTPUT_POLARITY_HIGH;
  hrtc.Init.OutPutType = RTC_OUTPUT_TYPE_OPENDRAIN;
  if (HAL_RTC_Init(&hrtc) != HAL_OK)
  {
    _Error_Handler(__FILE__, __LINE__);
  }

    /**Initialize RTC and set the Time and Date
    */
  if(HAL_RTCEx_BKUPRead(&hrtc, RTC_BKP_DR0) != 0x32F2){
  sTime.Hours = 0x0;
  sTime.Minutes = 0x0;
  sTime.Seconds = 0x0;
  sTime.DayLightSaving = RTC_DAYLIGHTSAVING_NONE;
  sTime.StoreOperation = RTC_STOREOPERATION_RESET;
  if (HAL_RTC_SetTime(&hrtc, &sTime, RTC_FORMAT_BCD) != HAL_OK)
  {
    _Error_Handler(__FILE__, __LINE__);
  }

  sDate.WeekDay = RTC_WEEKDAY_MONDAY;
  sDate.Month = RTC_MONTH_JANUARY;
  sDate.Date = 0x1;
  sDate.Year = 0x0;

  if (HAL_RTC_SetDate(&hrtc, &sDate, RTC_FORMAT_BCD) != HAL_OK)
  {
    _Error_Handler(__FILE__, __LINE__);
  }

    HAL_RTCEx_BKUPWrite(&hrtc,RTC_BKP_DR0,0x32F2);
  }
    /**Enable the Alarm A
    */
  sAlarm.AlarmTime.Hours = 0x0;
  sAlarm.AlarmTime.Minutes = 0x0;
  sAlarm.AlarmTime.Seconds = 0x0;
  sAlarm.AlarmTime.SubSeconds = 0x0;
  sAlarm.AlarmTime.DayLightSaving = RTC_DAYLIGHTSAVING_NONE;
  sAlarm.AlarmTime.StoreOperation = RTC_STOREOPERATION_RESET;
  sAlarm.AlarmMask = RTC_ALARMMASK_NONE;
  sAlarm.AlarmSubSecondMask = RTC_ALARMSUBSECONDMASK_ALL;
  sAlarm.AlarmDateWeekDaySel = RTC_ALARMDATEWEEKDAYSEL_DATE;
  sAlarm.AlarmDateWeekDay = 0x1;
  sAlarm.Alarm = RTC_ALARM_A;
  if (HAL_RTC_SetAlarm(&hrtc, &sAlarm, RTC_FORMAT_BCD) != HAL_OK)
  {
    _Error_Handler(__FILE__, __LINE__);
  }

    /**Enable the Alarm B
    */
  sAlarm.AlarmDateWeekDay = 0x1;
  sAlarm.Alarm = RTC_ALARM_B;
  if (HAL_RTC_SetAlarm(&hrtc, &sAlarm, RTC_FORMAT_BCD) != HAL_OK)
  {
    _Error_Handler(__FILE__, __LINE__);
  }

    /**Enable the TimeStamp
    */
  if (HAL_RTCEx_SetTimeStamp(&hrtc, RTC_TIMESTAMPEDGE_RISING, RTC_TIMESTAMPPIN_POS1) != HAL_OK)
  {
    _Error_Handler(__FILE__, __LINE__);
  }

}

/* SDMMC1 init function */
static void MX_SDMMC1_SD_Init(void)
{

  hsd1.Instance = SDMMC1;
  hsd1.Init.ClockEdge = SDMMC_CLOCK_EDGE_RISING;
  hsd1.Init.ClockBypass = SDMMC_CLOCK_BYPASS_DISABLE;
  hsd1.Init.ClockPowerSave = SDMMC_CLOCK_POWER_SAVE_DISABLE;
  hsd1.Init.BusWide = SDMMC_BUS_WIDE_1B;
  hsd1.Init.HardwareFlowControl = SDMMC_HARDWARE_FLOW_CONTROL_DISABLE;
  hsd1.Init.ClockDiv = 2;

}

/* SPDIFRX init function */
static void MX_SPDIFRX_Init(void)
{

  hspdif.Instance = SPDIFRX;
  hspdif.Init.InputSelection = SPDIFRX_INPUT_IN0;
  hspdif.Init.Retries = SPDIFRX_MAXRETRIES_NONE;
  hspdif.Init.WaitForActivity = SPDIFRX_WAITFORACTIVITY_OFF;
  hspdif.Init.ChannelSelection = SPDIFRX_CHANNEL_A;
  hspdif.Init.DataFormat = SPDIFRX_DATAFORMAT_LSB;
  hspdif.Init.StereoMode = SPDIFRX_STEREOMODE_DISABLE;
  hspdif.Init.PreambleTypeMask = SPDIFRX_PREAMBLETYPEMASK_OFF;
  hspdif.Init.ChannelStatusMask = SPDIFRX_CHANNELSTATUS_OFF;
  hspdif.Init.ValidityBitMask = SPDIFRX_VALIDITYMASK_OFF;
  hspdif.Init.ParityErrorMask = SPDIFRX_PARITYERRORMASK_OFF;
  if (HAL_SPDIFRX_Init(&hspdif) != HAL_OK)
  {
    _Error_Handler(__FILE__, __LINE__);
  }

}

/* SPI2 init function */
static void MX_SPI2_Init(void)
{

  hspi2.Instance = SPI2;
  hspi2.Init.Mode = SPI_MODE_MASTER;
  hspi2.Init.Direction = SPI_DIRECTION_2LINES;
  hspi2.Init.DataSize = SPI_DATASIZE_4BIT;
  hspi2.Init.CLKPolarity = SPI_POLARITY_LOW;
  hspi2.Init.CLKPhase = SPI_PHASE_1EDGE;
  hspi2.Init.NSS = SPI_NSS_SOFT;
  hspi2.Init.BaudRatePrescaler = SPI_BAUDRATEPRESCALER_2;
  hspi2.Init.FirstBit = SPI_FIRSTBIT_MSB;
  hspi2.Init.TIMode = SPI_TIMODE_DISABLE;
  hspi2.Init.CRCCalculation = SPI_CRCCALCULATION_DISABLE;
  hspi2.Init.CRCPolynomial = 7;
  hspi2.Init.CRCLength = SPI_CRC_LENGTH_DATASIZE;
  hspi2.Init.NSSPMode = SPI_NSS_PULSE_ENABLE;
  if (HAL_SPI_Init(&hspi2) != HAL_OK)
  {
    _Error_Handler(__FILE__, __LINE__);
  }

}

/* TIM1 init function */
static void MX_TIM1_Init(void)
{

  TIM_ClockConfigTypeDef sClockSourceConfig;
  TIM_MasterConfigTypeDef sMasterConfig;
  TIM_OC_InitTypeDef sConfigOC;
  TIM_BreakDeadTimeConfigTypeDef sBreakDeadTimeConfig;

  htim1.Instance = TIM1;
  htim1.Init.Prescaler = 0;
  htim1.Init.CounterMode = TIM_COUNTERMODE_UP;
  htim1.Init.Period = 0;
  htim1.Init.ClockDivision = TIM_CLOCKDIVISION_DIV1;
  htim1.Init.RepetitionCounter = 0;
  htim1.Init.AutoReloadPreload = TIM_AUTORELOAD_PRELOAD_DISABLE;
  if (HAL_TIM_Base_Init(&htim1) != HAL_OK)
  {
    _Error_Handler(__FILE__, __LINE__);
  }

  sClockSourceConfig.ClockSource = TIM_CLOCKSOURCE_INTERNAL;
  if (HAL_TIM_ConfigClockSource(&htim1, &sClockSourceConfig) != HAL_OK)
  {
    _Error_Handler(__FILE__, __LINE__);
  }

  if (HAL_TIM_PWM_Init(&htim1) != HAL_OK)
  {
    _Error_Handler(__FILE__, __LINE__);
  }

  sMasterConfig.MasterOutputTrigger = TIM_TRGO_RESET;
  sMasterConfig.MasterOutputTrigger2 = TIM_TRGO2_RESET;
  sMasterConfig.MasterSlaveMode = TIM_MASTERSLAVEMODE_DISABLE;
  if (HAL_TIMEx_MasterConfigSynchronization(&htim1, &sMasterConfig) != HAL_OK)
  {
    _Error_Handler(__FILE__, __LINE__);
  }

  sConfigOC.OCMode = TIM_OCMODE_PWM1;
  sConfigOC.Pulse = 0;
  sConfigOC.OCPolarity = TIM_OCPOLARITY_HIGH;
  sConfigOC.OCNPolarity = TIM_OCNPOLARITY_HIGH;
  sConfigOC.OCFastMode = TIM_OCFAST_DISABLE;
  sConfigOC.OCIdleState = TIM_OCIDLESTATE_RESET;
  sConfigOC.OCNIdleState = TIM_OCNIDLESTATE_RESET;
  if (HAL_TIM_PWM_ConfigChannel(&htim1, &sConfigOC, TIM_CHANNEL_1) != HAL_OK)
  {
    _Error_Handler(__FILE__, __LINE__);
  }

  sBreakDeadTimeConfig.OffStateRunMode = TIM_OSSR_DISABLE;
  sBreakDeadTimeConfig.OffStateIDLEMode = TIM_OSSI_DISABLE;
  sBreakDeadTimeConfig.LockLevel = TIM_LOCKLEVEL_OFF;
  sBreakDeadTimeConfig.DeadTime = 0;
  sBreakDeadTimeConfig.BreakState = TIM_BREAK_DISABLE;
  sBreakDeadTimeConfig.BreakPolarity = TIM_BREAKPOLARITY_HIGH;
  sBreakDeadTimeConfig.BreakFilter = 0;
  sBreakDeadTimeConfig.Break2State = TIM_BREAK2_DISABLE;
  sBreakDeadTimeConfig.Break2Polarity = TIM_BREAK2POLARITY_HIGH;
  sBreakDeadTimeConfig.Break2Filter = 0;
  sBreakDeadTimeConfig.AutomaticOutput = TIM_AUTOMATICOUTPUT_DISABLE;
  if (HAL_TIMEx_ConfigBreakDeadTime(&htim1, &sBreakDeadTimeConfig) != HAL_OK)
  {
    _Error_Handler(__FILE__, __LINE__);
  }

  HAL_TIM_MspPostInit(&htim1);

}

/* TIM2 init function */
static void MX_TIM2_Init(void)
{

  TIM_ClockConfigTypeDef sClockSourceConfig;
  TIM_MasterConfigTypeDef sMasterConfig;
  TIM_OC_InitTypeDef sConfigOC;

  htim2.Instance = TIM2;
  htim2.Init.Prescaler = 0;
  htim2.Init.CounterMode = TIM_COUNTERMODE_UP;
  htim2.Init.Period = 0;
  htim2.Init.ClockDivision = TIM_CLOCKDIVISION_DIV1;
  htim2.Init.AutoReloadPreload = TIM_AUTORELOAD_PRELOAD_DISABLE;
  if (HAL_TIM_Base_Init(&htim2) != HAL_OK)
  {
    _Error_Handler(__FILE__, __LINE__);
  }

  sClockSourceConfig.ClockSource = TIM_CLOCKSOURCE_INTERNAL;
  if (HAL_TIM_ConfigClockSource(&htim2, &sClockSourceConfig) != HAL_OK)
  {
    _Error_Handler(__FILE__, __LINE__);
  }

  if (HAL_TIM_PWM_Init(&htim2) != HAL_OK)
  {
    _Error_Handler(__FILE__, __LINE__);
  }

  sMasterConfig.MasterOutputTrigger = TIM_TRGO_RESET;
  sMasterConfig.MasterSlaveMode = TIM_MASTERSLAVEMODE_DISABLE;
  if (HAL_TIMEx_MasterConfigSynchronization(&htim2, &sMasterConfig) != HAL_OK)
  {
    _Error_Handler(__FILE__, __LINE__);
  }

  sConfigOC.OCMode = TIM_OCMODE_PWM1;
  sConfigOC.Pulse = 0;
  sConfigOC.OCPolarity = TIM_OCPOLARITY_HIGH;
  sConfigOC.OCFastMode = TIM_OCFAST_DISABLE;
  if (HAL_TIM_PWM_ConfigChannel(&htim2, &sConfigOC, TIM_CHANNEL_1) != HAL_OK)
  {
    _Error_Handler(__FILE__, __LINE__);
  }

  HAL_TIM_MspPostInit(&htim2);

}

/* TIM3 init function */
static void MX_TIM3_Init(void)
{

  TIM_ClockConfigTypeDef sClockSourceConfig;
  TIM_MasterConfigTypeDef sMasterConfig;
  TIM_OC_InitTypeDef sConfigOC;

  htim3.Instance = TIM3;
  htim3.Init.Prescaler = 0;
  htim3.Init.CounterMode = TIM_COUNTERMODE_UP;
  htim3.Init.Period = 0;
  htim3.Init.ClockDivision = TIM_CLOCKDIVISION_DIV1;
  htim3.Init.AutoReloadPreload = TIM_AUTORELOAD_PRELOAD_DISABLE;
  if (HAL_TIM_Base_Init(&htim3) != HAL_OK)
  {
    _Error_Handler(__FILE__, __LINE__);
  }

  sClockSourceConfig.ClockSource = TIM_CLOCKSOURCE_INTERNAL;
  if (HAL_TIM_ConfigClockSource(&htim3, &sClockSourceConfig) != HAL_OK)
  {
    _Error_Handler(__FILE__, __LINE__);
  }

  if (HAL_TIM_PWM_Init(&htim3) != HAL_OK)
  {
    _Error_Handler(__FILE__, __LINE__);
  }

  sMasterConfig.MasterOutputTrigger = TIM_TRGO_RESET;
  sMasterConfig.MasterSlaveMode = TIM_MASTERSLAVEMODE_DISABLE;
  if (HAL_TIMEx_MasterConfigSynchronization(&htim3, &sMasterConfig) != HAL_OK)
  {
    _Error_Handler(__FILE__, __LINE__);
  }

  sConfigOC.OCMode = TIM_OCMODE_PWM1;
  sConfigOC.Pulse = 0;
  sConfigOC.OCPolarity = TIM_OCPOLARITY_HIGH;
  sConfigOC.OCFastMode = TIM_OCFAST_DISABLE;
  if (HAL_TIM_PWM_ConfigChannel(&htim3, &sConfigOC, TIM_CHANNEL_1) != HAL_OK)
  {
    _Error_Handler(__FILE__, __LINE__);
  }

  HAL_TIM_MspPostInit(&htim3);

}

/* TIM5 init function */
static void MX_TIM5_Init(void)
{

  TIM_ClockConfigTypeDef sClockSourceConfig;
  TIM_MasterConfigTypeDef sMasterConfig;
  TIM_OC_InitTypeDef sConfigOC;

  htim5.Instance = TIM5;
  htim5.Init.Prescaler = 0;
  htim5.Init.CounterMode = TIM_COUNTERMODE_UP;
  htim5.Init.Period = 0;
  htim5.Init.ClockDivision = TIM_CLOCKDIVISION_DIV1;
  htim5.Init.AutoReloadPreload = TIM_AUTORELOAD_PRELOAD_DISABLE;
  if (HAL_TIM_Base_Init(&htim5) != HAL_OK)
  {
    _Error_Handler(__FILE__, __LINE__);
  }

  sClockSourceConfig.ClockSource = TIM_CLOCKSOURCE_INTERNAL;
  if (HAL_TIM_ConfigClockSource(&htim5, &sClockSourceConfig) != HAL_OK)
  {
    _Error_Handler(__FILE__, __LINE__);
  }

  if (HAL_TIM_PWM_Init(&htim5) != HAL_OK)
  {
    _Error_Handler(__FILE__, __LINE__);
  }

  sMasterConfig.MasterOutputTrigger = TIM_TRGO_RESET;
  sMasterConfig.MasterSlaveMode = TIM_MASTERSLAVEMODE_DISABLE;
  if (HAL_TIMEx_MasterConfigSynchronization(&htim5, &sMasterConfig) != HAL_OK)
  {
    _Error_Handler(__FILE__, __LINE__);
  }

  sConfigOC.OCMode = TIM_OCMODE_PWM1;
  sConfigOC.Pulse = 0;
  sConfigOC.OCPolarity = TIM_OCPOLARITY_HIGH;
  sConfigOC.OCFastMode = TIM_OCFAST_DISABLE;
  if (HAL_TIM_PWM_ConfigChannel(&htim5, &sConfigOC, TIM_CHANNEL_4) != HAL_OK)
  {
    _Error_Handler(__FILE__, __LINE__);
  }

  HAL_TIM_MspPostInit(&htim5);

}

/* TIM8 init function */
static void MX_TIM8_Init(void)
{

  TIM_ClockConfigTypeDef sClockSourceConfig;
  TIM_MasterConfigTypeDef sMasterConfig;

  htim8.Instance = TIM8;
  htim8.Init.Prescaler = 0;
  htim8.Init.CounterMode = TIM_COUNTERMODE_UP;
  htim8.Init.Period = 0;
  htim8.Init.ClockDivision = TIM_CLOCKDIVISION_DIV1;
  htim8.Init.RepetitionCounter = 0;
  htim8.Init.AutoReloadPreload = TIM_AUTORELOAD_PRELOAD_DISABLE;
  if (HAL_TIM_Base_Init(&htim8) != HAL_OK)
  {
    _Error_Handler(__FILE__, __LINE__);
  }

  sClockSourceConfig.ClockSource = TIM_CLOCKSOURCE_INTERNAL;
  if (HAL_TIM_ConfigClockSource(&htim8, &sClockSourceConfig) != HAL_OK)
  {
    _Error_Handler(__FILE__, __LINE__);
  }

  sMasterConfig.MasterOutputTrigger = TIM_TRGO_RESET;
  sMasterConfig.MasterOutputTrigger2 = TIM_TRGO2_RESET;
  sMasterConfig.MasterSlaveMode = TIM_MASTERSLAVEMODE_DISABLE;
  if (HAL_TIMEx_MasterConfigSynchronization(&htim8, &sMasterConfig) != HAL_OK)
  {
    _Error_Handler(__FILE__, __LINE__);
  }

}

/* TIM12 init function */
static void MX_TIM12_Init(void)
{

  TIM_OC_InitTypeDef sConfigOC;

  htim12.Instance = TIM12;
  htim12.Init.Prescaler = 0;
  htim12.Init.CounterMode = TIM_COUNTERMODE_UP;
  htim12.Init.Period = 0;
  htim12.Init.ClockDivision = TIM_CLOCKDIVISION_DIV1;
  htim12.Init.AutoReloadPreload = TIM_AUTORELOAD_PRELOAD_DISABLE;
  if (HAL_TIM_PWM_Init(&htim12) != HAL_OK)
  {
    _Error_Handler(__FILE__, __LINE__);
  }

  sConfigOC.OCMode = TIM_OCMODE_PWM1;
  sConfigOC.Pulse = 0;
  sConfigOC.OCPolarity = TIM_OCPOLARITY_HIGH;
  sConfigOC.OCFastMode = TIM_OCFAST_DISABLE;
  if (HAL_TIM_PWM_ConfigChannel(&htim12, &sConfigOC, TIM_CHANNEL_1) != HAL_OK)
  {
    _Error_Handler(__FILE__, __LINE__);
  }

  HAL_TIM_MspPostInit(&htim12);

}

/* USART1 init function */
static void MX_USART1_UART_Init(void)
{

  huart1.Instance = USART1;
  huart1.Init.BaudRate = 115200;
  huart1.Init.WordLength = UART_WORDLENGTH_7B;
  huart1.Init.StopBits = UART_STOPBITS_1;
  huart1.Init.Parity = UART_PARITY_NONE;
  huart1.Init.Mode = UART_MODE_TX_RX;
  huart1.Init.HwFlowCtl = UART_HWCONTROL_NONE;
  huart1.Init.OverSampling = UART_OVERSAMPLING_16;
  huart1.Init.OneBitSampling = UART_ONE_BIT_SAMPLE_DISABLE;
  huart1.AdvancedInit.AdvFeatureInit = UART_ADVFEATURE_NO_INIT;
  if (HAL_UART_Init(&huart1) != HAL_OK)
  {
    _Error_Handler(__FILE__, __LINE__);
  }

}

/* USART6 init function */
static void MX_USART6_UART_Init(void)
{

  huart6.Instance = USART6;
  huart6.Init.BaudRate = 115200;
  huart6.Init.WordLength = UART_WORDLENGTH_7B;
  huart6.Init.StopBits = UART_STOPBITS_1;
  huart6.Init.Parity = UART_PARITY_NONE;
  huart6.Init.Mode = UART_MODE_TX_RX;
  huart6.Init.HwFlowCtl = UART_HWCONTROL_NONE;
  huart6.Init.OverSampling = UART_OVERSAMPLING_16;
  huart6.Init.OneBitSampling = UART_ONE_BIT_SAMPLE_DISABLE;
  huart6.AdvancedInit.AdvFeatureInit = UART_ADVFEATURE_NO_INIT;
  if (HAL_UART_Init(&huart6) != HAL_OK)
  {
    _Error_Handler(__FILE__, __LINE__);
  }

}
/* FMC initialization function */
static void MX_FMC_Init(void)
{
  FMC_SDRAM_TimingTypeDef SdramTiming;

  /** Perform the SDRAM1 memory initialization sequence
  */
  hsdram1.Instance = FMC_SDRAM_DEVICE;
  /* hsdram1.Init */
  hsdram1.Init.SDBank = FMC_SDRAM_BANK1;
  hsdram1.Init.ColumnBitsNumber = FMC_SDRAM_COLUMN_BITS_NUM_8;
  hsdram1.Init.RowBitsNumber = FMC_SDRAM_ROW_BITS_NUM_12;
  hsdram1.Init.MemoryDataWidth = FMC_SDRAM_MEM_BUS_WIDTH_16;
  hsdram1.Init.InternalBankNumber = FMC_SDRAM_INTERN_BANKS_NUM_4;
  hsdram1.Init.CASLatency = FMC_SDRAM_CAS_LATENCY_1;
  hsdram1.Init.WriteProtection = FMC_SDRAM_WRITE_PROTECTION_DISABLE;
  hsdram1.Init.SDClockPeriod = FMC_SDRAM_CLOCK_DISABLE;
  hsdram1.Init.ReadBurst = FMC_SDRAM_RBURST_DISABLE;
  hsdram1.Init.ReadPipeDelay = FMC_SDRAM_RPIPE_DELAY_0;
  /* SdramTiming */
  SdramTiming.LoadToActiveDelay = 16;
  SdramTiming.ExitSelfRefreshDelay = 16;
  SdramTiming.SelfRefreshTime = 16;
  SdramTiming.RowCycleDelay = 16;
  SdramTiming.WriteRecoveryTime = 16;
  SdramTiming.RPDelay = 16;
  SdramTiming.RCDDelay = 16;

  if (HAL_SDRAM_Init(&hsdram1, &SdramTiming) != HAL_OK)
  {
    _Error_Handler(__FILE__, __LINE__);
  }

}

/** Configure pins as
        * Analog
        * Input
        * Output
        * EVENT_OUT
        * EXTI
     PG14   ------> ETH_TXD1
     PB5   ------> USB_OTG_HS_ULPI_D7
     PE5   ------> DCMI_D6
     PE6   ------> DCMI_D7
     PG13   ------> ETH_TXD0
     PG11   ------> ETH_TX_EN
     PA12   ------> USB_OTG_FS_DP
     PI4   ------> SAI2_MCLK_A
     PG10   ------> SAI2_SD_B
     PD3   ------> DCMI_D5
     PA11   ------> USB_OTG_FS_DM
     PI5   ------> SAI2_SCK_A
     PI7   ------> SAI2_FS_A
     PI6   ------> SAI2_SD_A
     PG9   ------> DCMI_VSYNC
     PA10   ------> USB_OTG_FS_ID
     PH14   ------> DCMI_D4
     PH4   ------> USB_OTG_HS_ULPI_NXT
     PB13   ------> USB_OTG_HS_ULPI_D6
     PB12   ------> USB_OTG_HS_ULPI_D5
     PC0   ------> USB_OTG_HS_ULPI_STP
     PC1   ------> ETH_MDC
     PC2   ------> USB_OTG_HS_ULPI_DIR
     PH12   ------> DCMI_D3
     PA1   ------> ETH_REF_CLK
     PA4   ------> DCMI_HSYNC
     PC4   ------> ETH_RXD0
     PH9   ------> DCMI_D0
     PH11   ------> DCMI_D2
     PA2   ------> ETH_MDIO
     PA6   ------> DCMI_PIXCLK
     PA5   ------> USB_OTG_HS_ULPI_CK
     PC5   ------> ETH_RXD1
     PB10   ------> USB_OTG_HS_ULPI_D3
     PH10   ------> DCMI_D1
     PA3   ------> USB_OTG_HS_ULPI_D0
     PA7   ------> ETH_CRS_DV
     PB1   ------> USB_OTG_HS_ULPI_D2
     PB0   ------> USB_OTG_HS_ULPI_D1
     PB11   ------> USB_OTG_HS_ULPI_D4
*/
static void MX_GPIO_Init(void)
{

  GPIO_InitTypeDef GPIO_InitStruct;

  /* GPIO Ports Clock Enable */
  __HAL_RCC_GPIOE_CLK_ENABLE();
  __HAL_RCC_GPIOG_CLK_ENABLE();
  __HAL_RCC_GPIOB_CLK_ENABLE();
  __HAL_RCC_GPIOD_CLK_ENABLE();
  __HAL_RCC_GPIOC_CLK_ENABLE();
  __HAL_RCC_GPIOA_CLK_ENABLE();
  __HAL_RCC_GPIOJ_CLK_ENABLE();
  __HAL_RCC_GPIOI_CLK_ENABLE();
  __HAL_RCC_GPIOK_CLK_ENABLE();
  __HAL_RCC_GPIOF_CLK_ENABLE();
  __HAL_RCC_GPIOH_CLK_ENABLE();

  /*Configure GPIO pin Output Level */
  HAL_GPIO_WritePin(OTG_FS_PowerSwitchOn_GPIO_Port, OTG_FS_PowerSwitchOn_Pin, GPIO_PIN_SET);

  /*Configure GPIO pin Output Level */
  HAL_GPIO_WritePin(GPIOI, ARDUINO_D7_Pin|ARDUINO_D8_Pin|LCD_DISP_Pin, GPIO_PIN_RESET);

  /*Configure GPIO pin Output Level */
  HAL_GPIO_WritePin(LCD_BL_CTRL_GPIO_Port, LCD_BL_CTRL_Pin, GPIO_PIN_RESET);

  /*Configure GPIO pin Output Level */
  HAL_GPIO_WritePin(DCMI_PWR_EN_GPIO_Port, DCMI_PWR_EN_Pin, GPIO_PIN_RESET);

  /*Configure GPIO pin Output Level */
  HAL_GPIO_WritePin(GPIOG, ARDUINO_D4_Pin|ARDUINO_D2_Pin|EXT_RST_Pin, GPIO_PIN_RESET);

  /*Configure GPIO pin : OTG_HS_OverCurrent_Pin */
  GPIO_InitStruct.Pin = OTG_HS_OverCurrent_Pin;
  GPIO_InitStruct.Mode = GPIO_MODE_INPUT;
  GPIO_InitStruct.Pull = GPIO_NOPULL;
  HAL_GPIO_Init(OTG_HS_OverCurrent_GPIO_Port, &GPIO_InitStruct);

  /*Configure GPIO pins : RMII_TXD1_Pin RMII_TXD0_Pin RMII_TX_EN_Pin */
  GPIO_InitStruct.Pin = RMII_TXD1_Pin|RMII_TXD0_Pin|RMII_TX_EN_Pin;
  GPIO_InitStruct.Mode = GPIO_MODE_AF_PP;
  GPIO_InitStruct.Pull = GPIO_NOPULL;
  GPIO_InitStruct.Speed = GPIO_SPEED_FREQ_VERY_HIGH;
  GPIO_InitStruct.Alternate = GPIO_AF11_ETH;
  HAL_GPIO_Init(GPIOG, &GPIO_InitStruct);

  /*Configure GPIO pins : ULPI_D7_Pin ULPI_D6_Pin ULPI_D5_Pin ULPI_D3_Pin
                           ULPI_D2_Pin ULPI_D1_Pin ULPI_D4_Pin */
  GPIO_InitStruct.Pin = ULPI_D7_Pin|ULPI_D6_Pin|ULPI_D5_Pin|ULPI_D3_Pin
                          |ULPI_D2_Pin|ULPI_D1_Pin|ULPI_D4_Pin;
  GPIO_InitStruct.Mode = GPIO_MODE_AF_PP;
  GPIO_InitStruct.Pull = GPIO_NOPULL;
  GPIO_InitStruct.Speed = GPIO_SPEED_FREQ_VERY_HIGH;
  GPIO_InitStruct.Alternate = GPIO_AF10_OTG_HS;
  HAL_GPIO_Init(GPIOB, &GPIO_InitStruct);

  /*Configure GPIO pins : DCMI_D6_Pin DCMI_D7_Pin */
  GPIO_InitStruct.Pin = DCMI_D6_Pin|DCMI_D7_Pin;
  GPIO_InitStruct.Mode = GPIO_MODE_AF_PP;
  GPIO_InitStruct.Pull = GPIO_NOPULL;
  GPIO_InitStruct.Speed = GPIO_SPEED_FREQ_LOW;
  GPIO_InitStruct.Alternate = GPIO_AF13_DCMI;
  HAL_GPIO_Init(GPIOE, &GPIO_InitStruct);

  /*Configure GPIO pin : OTG_FS_VBUS_Pin */
  GPIO_InitStruct.Pin = OTG_FS_VBUS_Pin;
  GPIO_InitStruct.Mode = GPIO_MODE_INPUT;
  GPIO_InitStruct.Pull = GPIO_NOPULL;
  HAL_GPIO_Init(OTG_FS_VBUS_GPIO_Port, &GPIO_InitStruct);

  /*Configure GPIO pin : Audio_INT_Pin */
  GPIO_InitStruct.Pin = Audio_INT_Pin;
  GPIO_InitStruct.Mode = GPIO_MODE_EVT_RISING;
  GPIO_InitStruct.Pull = GPIO_NOPULL;
  HAL_GPIO_Init(Audio_INT_GPIO_Port, &GPIO_InitStruct);

  /*Configure GPIO pins : OTG_FS_P_Pin OTG_FS_N_Pin OTG_FS_ID_Pin */
  GPIO_InitStruct.Pin = OTG_FS_P_Pin|OTG_FS_N_Pin|OTG_FS_ID_Pin;
  GPIO_InitStruct.Mode = GPIO_MODE_AF_PP;
  GPIO_InitStruct.Pull = GPIO_NOPULL;
  GPIO_InitStruct.Speed = GPIO_SPEED_FREQ_VERY_HIGH;
  GPIO_InitStruct.Alternate = GPIO_AF10_OTG_FS;
  HAL_GPIO_Init(GPIOA, &GPIO_InitStruct);

  /*Configure GPIO pins : SAI2_MCLKA_Pin SAI2_SCKA_Pin SAI2_FSA_Pin SAI2_SDA_Pin */
  GPIO_InitStruct.Pin = SAI2_MCLKA_Pin|SAI2_SCKA_Pin|SAI2_FSA_Pin|SAI2_SDA_Pin;
  GPIO_InitStruct.Mode = GPIO_MODE_AF_PP;
  GPIO_InitStruct.Pull = GPIO_NOPULL;
  GPIO_InitStruct.Speed = GPIO_SPEED_FREQ_LOW;
  GPIO_InitStruct.Alternate = GPIO_AF10_SAI2;
  HAL_GPIO_Init(GPIOI, &GPIO_InitStruct);

  /*Configure GPIO pin : SAI2_SDB_Pin */
  GPIO_InitStruct.Pin = SAI2_SDB_Pin;
  GPIO_InitStruct.Mode = GPIO_MODE_AF_PP;
  GPIO_InitStruct.Pull = GPIO_NOPULL;
  GPIO_InitStruct.Speed = GPIO_SPEED_FREQ_LOW;
  GPIO_InitStruct.Alternate = GPIO_AF10_SAI2;
  HAL_GPIO_Init(SAI2_SDB_GPIO_Port, &GPIO_InitStruct);

  /*Configure GPIO pin : OTG_FS_PowerSwitchOn_Pin */
  GPIO_InitStruct.Pin = OTG_FS_PowerSwitchOn_Pin;
  GPIO_InitStruct.Mode = GPIO_MODE_OUTPUT_PP;
  GPIO_InitStruct.Pull = GPIO_NOPULL;
  GPIO_InitStruct.Speed = GPIO_SPEED_FREQ_LOW;
  HAL_GPIO_Init(OTG_FS_PowerSwitchOn_GPIO_Port, &GPIO_InitStruct);

  /*Configure GPIO pin : DCMI_D5_Pin */
  GPIO_InitStruct.Pin = DCMI_D5_Pin;
  GPIO_InitStruct.Mode = GPIO_MODE_AF_PP;
  GPIO_InitStruct.Pull = GPIO_NOPULL;
  GPIO_InitStruct.Speed = GPIO_SPEED_FREQ_LOW;
  GPIO_InitStruct.Alternate = GPIO_AF13_DCMI;
  HAL_GPIO_Init(DCMI_D5_GPIO_Port, &GPIO_InitStruct);

  /*Configure GPIO pins : ARDUINO_D7_Pin ARDUINO_D8_Pin LCD_DISP_Pin */
  GPIO_InitStruct.Pin = ARDUINO_D7_Pin|ARDUINO_D8_Pin|LCD_DISP_Pin;
  GPIO_InitStruct.Mode = GPIO_MODE_OUTPUT_PP;
  GPIO_InitStruct.Pull = GPIO_NOPULL;
  GPIO_InitStruct.Speed = GPIO_SPEED_FREQ_LOW;
  HAL_GPIO_Init(GPIOI, &GPIO_InitStruct);

  /*Configure GPIO pin : uSD_Detect_Pin */
  GPIO_InitStruct.Pin = uSD_Detect_Pin;
  GPIO_InitStruct.Mode = GPIO_MODE_INPUT;
  GPIO_InitStruct.Pull = GPIO_NOPULL;
  HAL_GPIO_Init(uSD_Detect_GPIO_Port, &GPIO_InitStruct);

  /*Configure GPIO pin : LCD_BL_CTRL_Pin */
  GPIO_InitStruct.Pin = LCD_BL_CTRL_Pin;
  GPIO_InitStruct.Mode = GPIO_MODE_OUTPUT_PP;
  GPIO_InitStruct.Pull = GPIO_NOPULL;
  GPIO_InitStruct.Speed = GPIO_SPEED_FREQ_LOW;
  HAL_GPIO_Init(LCD_BL_CTRL_GPIO_Port, &GPIO_InitStruct);

  /*Configure GPIO pin : DCMI_VSYNC_Pin */
  GPIO_InitStruct.Pin = DCMI_VSYNC_Pin;
  GPIO_InitStruct.Mode = GPIO_MODE_AF_PP;
  GPIO_InitStruct.Pull = GPIO_NOPULL;
  GPIO_InitStruct.Speed = GPIO_SPEED_FREQ_LOW;
  GPIO_InitStruct.Alternate = GPIO_AF13_DCMI;
  HAL_GPIO_Init(DCMI_VSYNC_GPIO_Port, &GPIO_InitStruct);

  /*Configure GPIO pin : OTG_FS_OverCurrent_Pin */
  GPIO_InitStruct.Pin = OTG_FS_OverCurrent_Pin;
  GPIO_InitStruct.Mode = GPIO_MODE_INPUT;
  GPIO_InitStruct.Pull = GPIO_NOPULL;
  HAL_GPIO_Init(OTG_FS_OverCurrent_GPIO_Port, &GPIO_InitStruct);

  /*Configure GPIO pins : TP3_Pin NC2_Pin */
  GPIO_InitStruct.Pin = TP3_Pin|NC2_Pin;
  GPIO_InitStruct.Mode = GPIO_MODE_INPUT;
  GPIO_InitStruct.Pull = GPIO_NOPULL;
  HAL_GPIO_Init(GPIOH, &GPIO_InitStruct);

  /*Configure GPIO pin : DCMI_PWR_EN_Pin */
  GPIO_InitStruct.Pin = DCMI_PWR_EN_Pin;
  GPIO_InitStruct.Mode = GPIO_MODE_OUTPUT_PP;
  GPIO_InitStruct.Pull = GPIO_NOPULL;
  GPIO_InitStruct.Speed = GPIO_SPEED_FREQ_LOW;
  HAL_GPIO_Init(DCMI_PWR_EN_GPIO_Port, &GPIO_InitStruct);

  /*Configure GPIO pins : DCMI_D4_Pin DCMI_D3_Pin DCMI_D0_Pin DCMI_D2_Pin
                           DCMI_D1_Pin */
  GPIO_InitStruct.Pin = DCMI_D4_Pin|DCMI_D3_Pin|DCMI_D0_Pin|DCMI_D2_Pin
                          |DCMI_D1_Pin;
  GPIO_InitStruct.Mode = GPIO_MODE_AF_PP;
  GPIO_InitStruct.Pull = GPIO_NOPULL;
  GPIO_InitStruct.Speed = GPIO_SPEED_FREQ_LOW;
  GPIO_InitStruct.Alternate = GPIO_AF13_DCMI;
  HAL_GPIO_Init(GPIOH, &GPIO_InitStruct);

  /*Configure GPIO pin : LCD_INT_Pin */
  GPIO_InitStruct.Pin = LCD_INT_Pin;
  GPIO_InitStruct.Mode = GPIO_MODE_EVT_RISING;
  GPIO_InitStruct.Pull = GPIO_NOPULL;
  HAL_GPIO_Init(LCD_INT_GPIO_Port, &GPIO_InitStruct);

  /*Configure GPIO pin : ULPI_NXT_Pin */
  GPIO_InitStruct.Pin = ULPI_NXT_Pin;
  GPIO_InitStruct.Mode = GPIO_MODE_AF_PP;
  GPIO_InitStruct.Pull = GPIO_NOPULL;
  GPIO_InitStruct.Speed = GPIO_SPEED_FREQ_VERY_HIGH;
  GPIO_InitStruct.Alternate = GPIO_AF10_OTG_HS;
  HAL_GPIO_Init(ULPI_NXT_GPIO_Port, &GPIO_InitStruct);

  /*Configure GPIO pins : ARDUINO_D4_Pin ARDUINO_D2_Pin EXT_RST_Pin */
  GPIO_InitStruct.Pin = ARDUINO_D4_Pin|ARDUINO_D2_Pin|EXT_RST_Pin;
  GPIO_InitStruct.Mode = GPIO_MODE_OUTPUT_PP;
  GPIO_InitStruct.Pull = GPIO_NOPULL;
  GPIO_InitStruct.Speed = GPIO_SPEED_FREQ_LOW;
  HAL_GPIO_Init(GPIOG, &GPIO_InitStruct);

  /*Configure GPIO pins : ULPI_STP_Pin ULPI_DIR_Pin */
  GPIO_InitStruct.Pin = ULPI_STP_Pin|ULPI_DIR_Pin;
  GPIO_InitStruct.Mode = GPIO_MODE_AF_PP;
  GPIO_InitStruct.Pull = GPIO_NOPULL;
  GPIO_InitStruct.Speed = GPIO_SPEED_FREQ_VERY_HIGH;
  GPIO_InitStruct.Alternate = GPIO_AF10_OTG_HS;
  HAL_GPIO_Init(GPIOC, &GPIO_InitStruct);

  /*Configure GPIO pins : RMII_MDC_Pin RMII_RXD0_Pin RMII_RXD1_Pin */
  GPIO_InitStruct.Pin = RMII_MDC_Pin|RMII_RXD0_Pin|RMII_RXD1_Pin;
  GPIO_InitStruct.Mode = GPIO_MODE_AF_PP;
  GPIO_InitStruct.Pull = GPIO_NOPULL;
  GPIO_InitStruct.Speed = GPIO_SPEED_FREQ_VERY_HIGH;
  GPIO_InitStruct.Alternate = GPIO_AF11_ETH;
  HAL_GPIO_Init(GPIOC, &GPIO_InitStruct);

  /*Configure GPIO pin : RMII_RXER_Pin */
  GPIO_InitStruct.Pin = RMII_RXER_Pin;
  GPIO_InitStruct.Mode = GPIO_MODE_INPUT;
  GPIO_InitStruct.Pull = GPIO_NOPULL;
  HAL_GPIO_Init(RMII_RXER_GPIO_Port, &GPIO_InitStruct);

  /*Configure GPIO pins : RMII_REF_CLK_Pin RMII_MDIO_Pin RMII_CRS_DV_Pin */
  GPIO_InitStruct.Pin = RMII_REF_CLK_Pin|RMII_MDIO_Pin|RMII_CRS_DV_Pin;
  GPIO_InitStruct.Mode = GPIO_MODE_AF_PP;
  GPIO_InitStruct.Pull = GPIO_NOPULL;
  GPIO_InitStruct.Speed = GPIO_SPEED_FREQ_VERY_HIGH;
  GPIO_InitStruct.Alternate = GPIO_AF11_ETH;
  HAL_GPIO_Init(GPIOA, &GPIO_InitStruct);

  /*Configure GPIO pins : DCMI_HSYNC_Pin PA6 */
  GPIO_InitStruct.Pin = DCMI_HSYNC_Pin|GPIO_PIN_6;
  GPIO_InitStruct.Mode = GPIO_MODE_AF_PP;
  GPIO_InitStruct.Pull = GPIO_NOPULL;
  GPIO_InitStruct.Speed = GPIO_SPEED_FREQ_LOW;
  GPIO_InitStruct.Alternate = GPIO_AF13_DCMI;
  HAL_GPIO_Init(GPIOA, &GPIO_InitStruct);

  /*Configure GPIO pins : ULPI_CLK_Pin ULPI_D0_Pin */
  GPIO_InitStruct.Pin = ULPI_CLK_Pin|ULPI_D0_Pin;
  GPIO_InitStruct.Mode = GPIO_MODE_AF_PP;
  GPIO_InitStruct.Pull = GPIO_NOPULL;
  GPIO_InitStruct.Speed = GPIO_SPEED_FREQ_VERY_HIGH;
  GPIO_InitStruct.Alternate = GPIO_AF10_OTG_HS;
  HAL_GPIO_Init(GPIOA, &GPIO_InitStruct);

}

/* USER CODE BEGIN 4 */
void sdcardemo()
{

}
/* USER CODE END 4 */

void _Error_Handler(char * file, int line)
{
  while(1)
  {
  }
}

/************************ (C) COPYRIGHT STMicroelectronics *****END OF FILE****/
